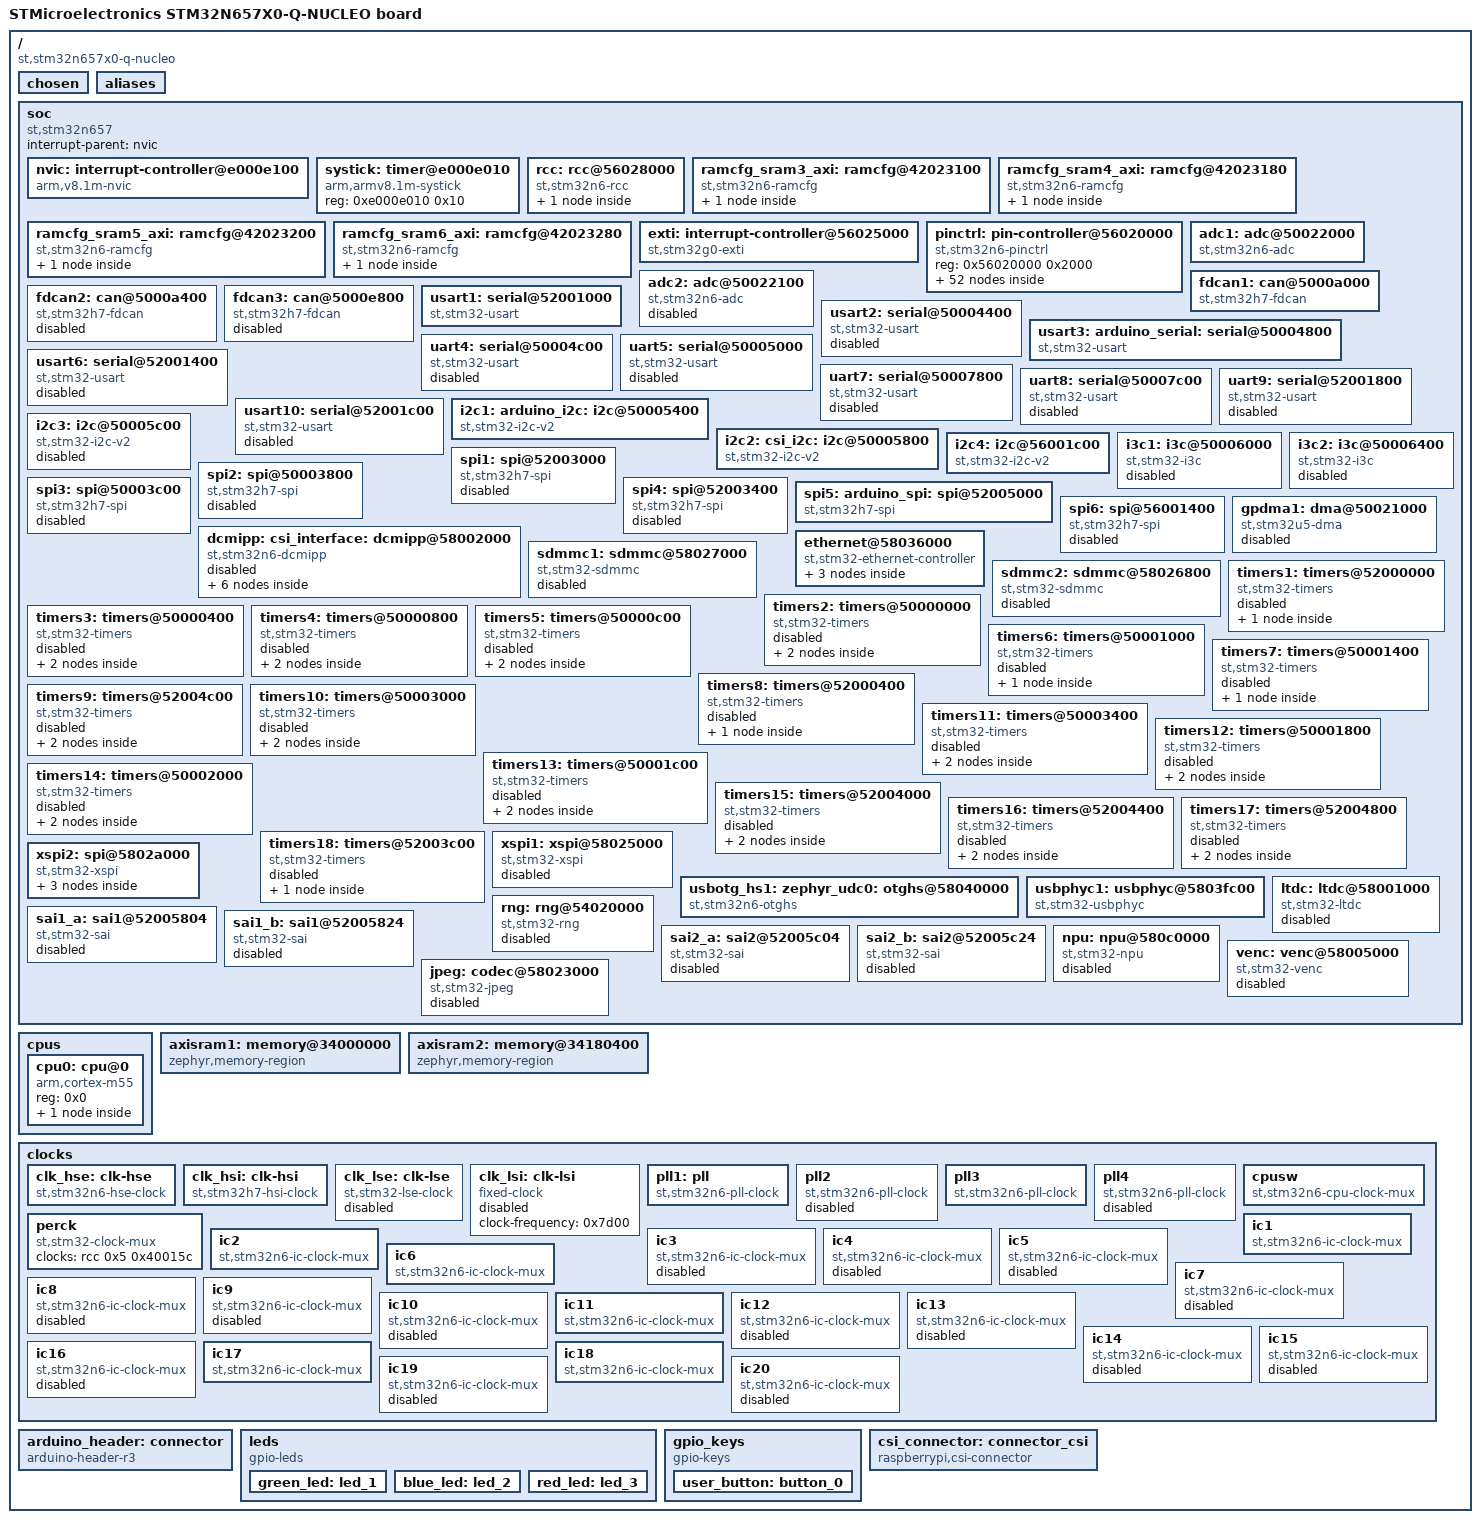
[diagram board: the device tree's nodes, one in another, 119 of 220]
/dts-v1/;

/* node '/' defined in zephyr/dts/common/skeleton.dtsi:9 */
/ {
	#address-cells = < 0x1 >;                                /* in zephyr/dts/common/skeleton.dtsi:10 */
	#size-cells = < 0x1 >;                                   /* in zephyr/dts/common/skeleton.dtsi:11 */
	model = "STMicroelectronics STM32N657X0-Q-NUCLEO board"; /* in zephyr/boards/st/nucleo_n657x0_q/nucleo_n657x0_q.dts:11 */
	compatible = "st,stm32n657x0-q-nucleo";                  /* in zephyr/boards/st/nucleo_n657x0_q/nucleo_n657x0_q.dts:12 */

	/* node '/chosen' defined in zephyr/dts/common/skeleton.dtsi:13 */
	chosen {
		zephyr,console = &usart1;    /* in zephyr/boards/st/nucleo_n657x0_q/nucleo_n657x0_q_common.dtsi:16 */
		zephyr,shell-uart = &usart1; /* in zephyr/boards/st/nucleo_n657x0_q/nucleo_n657x0_q_common.dtsi:17 */
		zephyr,sram = &axisram2;     /* in zephyr/boards/st/nucleo_n657x0_q/nucleo_n657x0_q_common.dtsi:18 */
		zephyr,canbus = &fdcan1;     /* in zephyr/boards/st/nucleo_n657x0_q/nucleo_n657x0_q_common.dtsi:19 */
		spi-flash0 = &mx25um51245g;  /* in zephyr/boards/st/nucleo_n657x0_q/nucleo_n657x0_q_common.dtsi:20 */
	};

	/* node '/aliases' defined in zephyr/dts/common/skeleton.dtsi:15 */
	aliases {
		led0 = &green_led;  /* in zephyr/boards/st/nucleo_n657x0_q/nucleo_n657x0_q_common.dtsi:53 */
		led1 = &blue_led;   /* in zephyr/boards/st/nucleo_n657x0_q/nucleo_n657x0_q_common.dtsi:54 */
		led2 = &red_led;    /* in zephyr/boards/st/nucleo_n657x0_q/nucleo_n657x0_q_common.dtsi:55 */
		sw0 = &user_button; /* in zephyr/boards/st/nucleo_n657x0_q/nucleo_n657x0_q_common.dtsi:56 */
	};

	/* node '/soc' defined in zephyr/dts/arm/armv8.1-m.dtsi:10 */
	soc {
		#address-cells = < 0x1 >;     /* in zephyr/dts/arm/armv8.1-m.dtsi:11 */
		#size-cells = < 0x1 >;        /* in zephyr/dts/arm/armv8.1-m.dtsi:12 */
		interrupt-parent = < &nvic >; /* in zephyr/dts/arm/armv8.1-m.dtsi:14 */
		ranges;                       /* in zephyr/dts/arm/armv8.1-m.dtsi:15 */
		compatible = "st,stm32n657",
		             "st,stm32n6",
		             "simple-bus";    /* in zephyr/dts/arm/st/n6/stm32n657.dtsi:11 */

		/* node '/soc/interrupt-controller@e000e100' defined in zephyr/dts/arm/armv8.1-m.dtsi:17 */
		nvic: interrupt-controller@e000e100 {
			#address-cells = < 0x1 >;            /* in zephyr/dts/arm/armv8.1-m.dtsi:18 */
			compatible = "arm,v8.1m-nvic";       /* in zephyr/dts/arm/armv8.1-m.dtsi:19 */
			reg = < 0xe000e100 0xc00 >;          /* in zephyr/dts/arm/armv8.1-m.dtsi:20 */
			interrupt-controller;                /* in zephyr/dts/arm/armv8.1-m.dtsi:21 */
			#interrupt-cells = < 0x2 >;          /* in zephyr/dts/arm/armv8.1-m.dtsi:22 */
			arm,num-irq-priority-bits = < 0x4 >; /* in zephyr/dts/arm/st/n6/stm32n6.dtsi:1336 */
			phandle = < 0x1 >;                   /* in zephyr/dts/arm/armv8.1-m.dtsi:14 */
		};

		/* node '/soc/timer@e000e010' defined in zephyr/dts/arm/armv8.1-m.dtsi:25 */
		systick: timer@e000e010 {
			compatible = "arm,armv8.1m-systick"; /* in zephyr/dts/arm/armv8.1-m.dtsi:26 */
			reg = < 0xe000e010 0x10 >;           /* in zephyr/dts/arm/armv8.1-m.dtsi:27 */
		};

		/* node '/soc/rcc@56028000' defined in zephyr/dts/arm/st/n6/stm32n6.dtsi:239 */
		rcc: rcc@56028000 {
			compatible = "st,stm32n6-rcc";    /* in zephyr/dts/arm/st/n6/stm32n6.dtsi:240 */
			clocks-controller;                /* in zephyr/dts/arm/st/n6/stm32n6.dtsi:241 */
			#clock-cells = < 0x2 >;           /* in zephyr/dts/arm/st/n6/stm32n6.dtsi:242 */
			reg = < 0x56028000 0x2000 >;      /* in zephyr/dts/arm/st/n6/stm32n6.dtsi:243 */
			clocks = < &ic2 >;                /* in zephyr/boards/st/nucleo_n657x0_q/nucleo_n657x0_q_common.dtsi:166 */
			clock-frequency = < 0x17d78400 >; /* in zephyr/boards/st/nucleo_n657x0_q/nucleo_n657x0_q_common.dtsi:167 */
			ahb-prescaler = < 0x2 >;          /* in zephyr/boards/st/nucleo_n657x0_q/nucleo_n657x0_q_common.dtsi:168 */
			timg-prescaler = < 0x2 >;         /* in zephyr/boards/st/nucleo_n657x0_q/nucleo_n657x0_q_common.dtsi:169 */
			phandle = < 0x3 >;                /* in zephyr/dts/arm/st/n6/stm32n6.dtsi:256 */

			/* node '/soc/rcc@56028000/reset-controller' defined in zephyr/dts/arm/st/n6/stm32n6.dtsi:245 */
			rctl: reset-controller {
				compatible = "st,stm32-rcc-rctl"; /* in zephyr/dts/arm/st/n6/stm32n6.dtsi:246 */
				#reset-cells = < 0x1 >;           /* in zephyr/dts/arm/st/n6/stm32n6.dtsi:247 */
				phandle = < 0x8 >;                /* in zephyr/dts/arm/st/n6/stm32n6.dtsi:513 */
			};
		};

		/* node '/soc/ramcfg@42023100' defined in zephyr/dts/arm/st/n6/stm32n6.dtsi:251 */
		ramcfg_sram3_axi: ramcfg@42023100 {
			compatible = "st,stm32n6-ramcfg"; /* in zephyr/dts/arm/st/n6/stm32n6.dtsi:252 */
			#address-cells = < 0x1 >;         /* in zephyr/dts/arm/st/n6/stm32n6.dtsi:253 */
			#size-cells = < 0x1 >;            /* in zephyr/dts/arm/st/n6/stm32n6.dtsi:254 */
			reg = < 0x42023100 0x80 >;        /* in zephyr/dts/arm/st/n6/stm32n6.dtsi:255 */
			clocks = < &rcc 0x24c 0x1 >,
			         < &rcc 0x254 0x1000 >;   /* in zephyr/dts/arm/st/n6/stm32n6.dtsi:256 */
			clock-names = "axisram",
			              "ramcfg";           /* in zephyr/dts/arm/st/n6/stm32n6.dtsi:257 */

			/* node '/soc/ramcfg@42023100/memory@34200000' defined in zephyr/dts/arm/st/n6/stm32n6.dtsi:259 */
			axisram3: memory@34200000 {
				compatible = "zephyr,memory-region",
				             "mmio-sram";            /* in zephyr/dts/arm/st/n6/stm32n6.dtsi:260 */
				zephyr,memory-region = "AXISRAM3";   /* in zephyr/dts/arm/st/n6/stm32n6.dtsi:261 */
				zephyr,memory-attr = < 0x100000 >;   /* in zephyr/dts/arm/st/n6/stm32n6.dtsi:262 */
				reg = < 0x34200000 0x70000 >;        /* in zephyr/dts/arm/st/n6/stm32n657X0.dtsi:23 */
				status = "disabled";                 /* in zephyr/dts/arm/st/n6/stm32n657X0.dtsi:24 */
			};
		};

		/* node '/soc/ramcfg@42023180' defined in zephyr/dts/arm/st/n6/stm32n6.dtsi:266 */
		ramcfg_sram4_axi: ramcfg@42023180 {
			compatible = "st,stm32n6-ramcfg"; /* in zephyr/dts/arm/st/n6/stm32n6.dtsi:267 */
			#address-cells = < 0x1 >;         /* in zephyr/dts/arm/st/n6/stm32n6.dtsi:268 */
			#size-cells = < 0x1 >;            /* in zephyr/dts/arm/st/n6/stm32n6.dtsi:269 */
			reg = < 0x42023180 0x80 >;        /* in zephyr/dts/arm/st/n6/stm32n6.dtsi:270 */
			clocks = < &rcc 0x24c 0x2 >,
			         < &rcc 0x254 0x1000 >;   /* in zephyr/dts/arm/st/n6/stm32n6.dtsi:271 */
			clock-names = "axisram",
			              "ramcfg";           /* in zephyr/dts/arm/st/n6/stm32n6.dtsi:272 */

			/* node '/soc/ramcfg@42023180/memory@34270000' defined in zephyr/dts/arm/st/n6/stm32n6.dtsi:274 */
			axisram4: memory@34270000 {
				compatible = "zephyr,memory-region",
				             "mmio-sram";            /* in zephyr/dts/arm/st/n6/stm32n6.dtsi:275 */
				zephyr,memory-region = "AXISRAM4";   /* in zephyr/dts/arm/st/n6/stm32n6.dtsi:276 */
				zephyr,memory-attr = < 0x100000 >;   /* in zephyr/dts/arm/st/n6/stm32n6.dtsi:277 */
				reg = < 0x34270000 0x70000 >;        /* in zephyr/dts/arm/st/n6/stm32n657X0.dtsi:30 */
				status = "disabled";                 /* in zephyr/dts/arm/st/n6/stm32n657X0.dtsi:31 */
			};
		};

		/* node '/soc/ramcfg@42023200' defined in zephyr/dts/arm/st/n6/stm32n6.dtsi:281 */
		ramcfg_sram5_axi: ramcfg@42023200 {
			compatible = "st,stm32n6-ramcfg"; /* in zephyr/dts/arm/st/n6/stm32n6.dtsi:282 */
			#address-cells = < 0x1 >;         /* in zephyr/dts/arm/st/n6/stm32n6.dtsi:283 */
			#size-cells = < 0x1 >;            /* in zephyr/dts/arm/st/n6/stm32n6.dtsi:284 */
			reg = < 0x42023200 0x80 >;        /* in zephyr/dts/arm/st/n6/stm32n6.dtsi:285 */
			clocks = < &rcc 0x24c 0x4 >,
			         < &rcc 0x254 0x1000 >;   /* in zephyr/dts/arm/st/n6/stm32n6.dtsi:286 */
			clock-names = "axisram",
			              "ramcfg";           /* in zephyr/dts/arm/st/n6/stm32n6.dtsi:287 */

			/* node '/soc/ramcfg@42023200/memory@342e0000' defined in zephyr/dts/arm/st/n6/stm32n6.dtsi:289 */
			axisram5: memory@342e0000 {
				compatible = "zephyr,memory-region",
				             "mmio-sram";            /* in zephyr/dts/arm/st/n6/stm32n6.dtsi:290 */
				zephyr,memory-region = "AXISRAM5";   /* in zephyr/dts/arm/st/n6/stm32n6.dtsi:291 */
				zephyr,memory-attr = < 0x100000 >;   /* in zephyr/dts/arm/st/n6/stm32n6.dtsi:292 */
				reg = < 0x342e0000 0x70000 >;        /* in zephyr/dts/arm/st/n6/stm32n657X0.dtsi:37 */
				status = "disabled";                 /* in zephyr/dts/arm/st/n6/stm32n657X0.dtsi:38 */
			};
		};

		/* node '/soc/ramcfg@42023280' defined in zephyr/dts/arm/st/n6/stm32n6.dtsi:296 */
		ramcfg_sram6_axi: ramcfg@42023280 {
			compatible = "st,stm32n6-ramcfg"; /* in zephyr/dts/arm/st/n6/stm32n6.dtsi:297 */
			#address-cells = < 0x1 >;         /* in zephyr/dts/arm/st/n6/stm32n6.dtsi:298 */
			#size-cells = < 0x1 >;            /* in zephyr/dts/arm/st/n6/stm32n6.dtsi:299 */
			reg = < 0x42023280 0x80 >;        /* in zephyr/dts/arm/st/n6/stm32n6.dtsi:300 */
			clocks = < &rcc 0x24c 0x8 >,
			         < &rcc 0x254 0x1000 >;   /* in zephyr/dts/arm/st/n6/stm32n6.dtsi:301 */
			clock-names = "axisram",
			              "ramcfg";           /* in zephyr/dts/arm/st/n6/stm32n6.dtsi:302 */

			/* node '/soc/ramcfg@42023280/memory@34350000' defined in zephyr/dts/arm/st/n6/stm32n6.dtsi:304 */
			axisram6: memory@34350000 {
				compatible = "zephyr,memory-region",
				             "mmio-sram";            /* in zephyr/dts/arm/st/n6/stm32n6.dtsi:305 */
				zephyr,memory-region = "AXISRAM6";   /* in zephyr/dts/arm/st/n6/stm32n6.dtsi:306 */
				zephyr,memory-attr = < 0x100000 >;   /* in zephyr/dts/arm/st/n6/stm32n6.dtsi:307 */
				reg = < 0x34350000 0x70000 >;        /* in zephyr/dts/arm/st/n6/stm32n657X0.dtsi:44 */
				status = "disabled";                 /* in zephyr/dts/arm/st/n6/stm32n657X0.dtsi:45 */
			};
		};

		/* node '/soc/interrupt-controller@56025000' defined in zephyr/dts/arm/st/n6/stm32n6.dtsi:311 */
		exti: interrupt-controller@56025000 {
			compatible = "st,stm32g0-exti",
			             "st,stm32-exti";   /* in zephyr/dts/arm/st/n6/stm32n6.dtsi:312 */
			interrupt-controller;           /* in zephyr/dts/arm/st/n6/stm32n6.dtsi:313 */
			#interrupt-cells = < 0x1 >;     /* in zephyr/dts/arm/st/n6/stm32n6.dtsi:314 */
			#address-cells = < 0x0 >;       /* in zephyr/dts/arm/st/n6/stm32n6.dtsi:315 */
			reg = < 0x56025000 0x400 >;     /* in zephyr/dts/arm/st/n6/stm32n6.dtsi:316 */
			clocks = < &rcc 0x278 0x1 >;    /* in zephyr/dts/arm/st/n6/stm32n6.dtsi:317 */
			num-lines = < 0x60 >;           /* in zephyr/dts/arm/st/n6/stm32n6.dtsi:318 */
			interrupts = < 0x14 0x0 >,
			             < 0x15 0x0 >,
			             < 0x16 0x0 >,
			             < 0x17 0x0 >,
			             < 0x18 0x0 >,
			             < 0x19 0x0 >,
			             < 0x1a 0x0 >,
			             < 0x1b 0x0 >,
			             < 0x1c 0x0 >,
			             < 0x1d 0x0 >,
			             < 0x1e 0x0 >,
			             < 0x1f 0x0 >,
			             < 0x20 0x0 >,
			             < 0x21 0x0 >,
			             < 0x22 0x0 >,
			             < 0x23 0x0 >;      /* in zephyr/dts/arm/st/n6/stm32n6.dtsi:319 */
			interrupt-names = "line0",
			                  "line1",
			                  "line2",
			                  "line3",
			                  "line4",
			                  "line5",
			                  "line6",
			                  "line7",
			                  "line8",
			                  "line9",
			                  "line10",
			                  "line11",
			                  "line12",
			                  "line13",
			                  "line14",
			                  "line15";     /* in zephyr/dts/arm/st/n6/stm32n6.dtsi:323 */
			line-ranges = < 0x0 0x1 >,
			              < 0x1 0x1 >,
			              < 0x2 0x1 >,
			              < 0x3 0x1 >,
			              < 0x4 0x1 >,
			              < 0x5 0x1 >,
			              < 0x6 0x1 >,
			              < 0x7 0x1 >,
			              < 0x8 0x1 >,
			              < 0x9 0x1 >,
			              < 0xa 0x1 >,
			              < 0xb 0x1 >,
			              < 0xc 0x1 >,
			              < 0xd 0x1 >,
			              < 0xe 0x1 >,
			              < 0xf 0x1 >;      /* in zephyr/dts/arm/st/n6/stm32n6.dtsi:327 */
		};

		/* node '/soc/pin-controller@56020000' defined in zephyr/dts/arm/st/n6/stm32n6.dtsi:333 */
		pinctrl: pin-controller@56020000 {
			compatible = "st,stm32n6-pinctrl",
			             "st,stm32-pinctrl";   /* in zephyr/dts/arm/st/n6/stm32n6.dtsi:334 */
			#address-cells = < 0x1 >;          /* in zephyr/dts/arm/st/n6/stm32n6.dtsi:335 */
			#size-cells = < 0x1 >;             /* in zephyr/dts/arm/st/n6/stm32n6.dtsi:336 */
			reg = < 0x56020000 0x2000 >;       /* in zephyr/dts/arm/st/n6/stm32n6.dtsi:337 */

			/* node '/soc/pin-controller@56020000/gpio@56020000' defined in zephyr/dts/arm/st/n6/stm32n6.dtsi:339 */
			gpioa: gpio@56020000 {
				compatible = "st,stm32-gpio"; /* in zephyr/dts/arm/st/n6/stm32n6.dtsi:340 */
				gpio-controller;              /* in zephyr/dts/arm/st/n6/stm32n6.dtsi:341 */
				#gpio-cells = < 0x2 >;        /* in zephyr/dts/arm/st/n6/stm32n6.dtsi:342 */
				reg = < 0x56020000 0x400 >;   /* in zephyr/dts/arm/st/n6/stm32n6.dtsi:343 */
				clocks = < &rcc 0x25c 0x1 >;  /* in zephyr/dts/arm/st/n6/stm32n6.dtsi:344 */
				phandle = < 0x2f >;           /* in zephyr/boards/st/nucleo_n657x0_q/arduino_r3_connector.dtsi:15 */

				/* node '/soc/pin-controller@56020000/gpio@56020000/csi-gpio1-hog' defined in zephyr/boards/st/nucleo_n657x0_q/nucleo_n657x0_q_common.dtsi:79 */
				csi_gpio1_hog: csi-gpio1-hog {
					gpio-hog;            /* in zephyr/boards/st/nucleo_n657x0_q/nucleo_n657x0_q_common.dtsi:80 */
					gpios = < 0x0 0x0 >; /* in zephyr/boards/st/nucleo_n657x0_q/nucleo_n657x0_q_common.dtsi:81 */
					status = "disabled"; /* in zephyr/boards/st/nucleo_n657x0_q/nucleo_n657x0_q_common.dtsi:83 */
				};
			};

			/* node '/soc/pin-controller@56020000/gpio@56020400' defined in zephyr/dts/arm/st/n6/stm32n6.dtsi:347 */
			gpiob: gpio@56020400 {
				compatible = "st,stm32-gpio"; /* in zephyr/dts/arm/st/n6/stm32n6.dtsi:348 */
				gpio-controller;              /* in zephyr/dts/arm/st/n6/stm32n6.dtsi:349 */
				#gpio-cells = < 0x2 >;        /* in zephyr/dts/arm/st/n6/stm32n6.dtsi:350 */
				reg = < 0x56020400 0x400 >;   /* in zephyr/dts/arm/st/n6/stm32n6.dtsi:351 */
				clocks = < &rcc 0x25c 0x2 >;  /* in zephyr/dts/arm/st/n6/stm32n6.dtsi:352 */
			};

			/* node '/soc/pin-controller@56020000/gpio@56020800' defined in zephyr/dts/arm/st/n6/stm32n6.dtsi:355 */
			gpioc: gpio@56020800 {
				compatible = "st,stm32-gpio"; /* in zephyr/dts/arm/st/n6/stm32n6.dtsi:356 */
				gpio-controller;              /* in zephyr/dts/arm/st/n6/stm32n6.dtsi:357 */
				#gpio-cells = < 0x2 >;        /* in zephyr/dts/arm/st/n6/stm32n6.dtsi:358 */
				reg = < 0x56020800 0x400 >;   /* in zephyr/dts/arm/st/n6/stm32n6.dtsi:359 */
				clocks = < &rcc 0x25c 0x4 >;  /* in zephyr/dts/arm/st/n6/stm32n6.dtsi:360 */
				phandle = < 0x34 >;           /* in zephyr/boards/st/nucleo_n657x0_q/arduino_r3_connector.dtsi:15 */
			};

			/* node '/soc/pin-controller@56020000/gpio@56020c00' defined in zephyr/dts/arm/st/n6/stm32n6.dtsi:363 */
			gpiod: gpio@56020c00 {
				compatible = "st,stm32-gpio"; /* in zephyr/dts/arm/st/n6/stm32n6.dtsi:364 */
				gpio-controller;              /* in zephyr/dts/arm/st/n6/stm32n6.dtsi:365 */
				#gpio-cells = < 0x2 >;        /* in zephyr/dts/arm/st/n6/stm32n6.dtsi:366 */
				reg = < 0x56020c00 0x400 >;   /* in zephyr/dts/arm/st/n6/stm32n6.dtsi:367 */
				clocks = < &rcc 0x25c 0x8 >;  /* in zephyr/dts/arm/st/n6/stm32n6.dtsi:368 */
				phandle = < 0x32 >;           /* in zephyr/boards/st/nucleo_n657x0_q/arduino_r3_connector.dtsi:15 */
			};

			/* node '/soc/pin-controller@56020000/gpio@56021000' defined in zephyr/dts/arm/st/n6/stm32n6.dtsi:371 */
			gpioe: gpio@56021000 {
				compatible = "st,stm32-gpio"; /* in zephyr/dts/arm/st/n6/stm32n6.dtsi:372 */
				gpio-controller;              /* in zephyr/dts/arm/st/n6/stm32n6.dtsi:373 */
				#gpio-cells = < 0x2 >;        /* in zephyr/dts/arm/st/n6/stm32n6.dtsi:374 */
				reg = < 0x56021000 0x400 >;   /* in zephyr/dts/arm/st/n6/stm32n6.dtsi:375 */
				clocks = < &rcc 0x25c 0x10 >; /* in zephyr/dts/arm/st/n6/stm32n6.dtsi:376 */
				phandle = < 0x33 >;           /* in zephyr/boards/st/nucleo_n657x0_q/arduino_r3_connector.dtsi:15 */
			};

			/* node '/soc/pin-controller@56020000/gpio@56021400' defined in zephyr/dts/arm/st/n6/stm32n6.dtsi:379 */
			gpiof: gpio@56021400 {
				compatible = "st,stm32-gpio"; /* in zephyr/dts/arm/st/n6/stm32n6.dtsi:380 */
				gpio-controller;              /* in zephyr/dts/arm/st/n6/stm32n6.dtsi:381 */
				#gpio-cells = < 0x2 >;        /* in zephyr/dts/arm/st/n6/stm32n6.dtsi:382 */
				reg = < 0x56021400 0x400 >;   /* in zephyr/dts/arm/st/n6/stm32n6.dtsi:383 */
				clocks = < &rcc 0x25c 0x20 >; /* in zephyr/dts/arm/st/n6/stm32n6.dtsi:384 */
				phandle = < 0x30 >;           /* in zephyr/boards/st/nucleo_n657x0_q/arduino_r3_connector.dtsi:15 */
			};

			/* node '/soc/pin-controller@56020000/gpio@56021800' defined in zephyr/dts/arm/st/n6/stm32n6.dtsi:387 */
			gpiog: gpio@56021800 {
				compatible = "st,stm32-gpio"; /* in zephyr/dts/arm/st/n6/stm32n6.dtsi:388 */
				gpio-controller;              /* in zephyr/dts/arm/st/n6/stm32n6.dtsi:389 */
				#gpio-cells = < 0x2 >;        /* in zephyr/dts/arm/st/n6/stm32n6.dtsi:390 */
				reg = < 0x56021800 0x400 >;   /* in zephyr/dts/arm/st/n6/stm32n6.dtsi:391 */
				clocks = < &rcc 0x25c 0x40 >; /* in zephyr/dts/arm/st/n6/stm32n6.dtsi:392 */
				phandle = < 0x31 >;           /* in zephyr/boards/st/nucleo_n657x0_q/arduino_r3_connector.dtsi:15 */
			};

			/* node '/soc/pin-controller@56020000/gpio@56021c00' defined in zephyr/dts/arm/st/n6/stm32n6.dtsi:395 */
			gpioh: gpio@56021c00 {
				compatible = "st,stm32-gpio"; /* in zephyr/dts/arm/st/n6/stm32n6.dtsi:396 */
				gpio-controller;              /* in zephyr/dts/arm/st/n6/stm32n6.dtsi:397 */
				#gpio-cells = < 0x2 >;        /* in zephyr/dts/arm/st/n6/stm32n6.dtsi:398 */
				reg = < 0x56021c00 0x400 >;   /* in zephyr/dts/arm/st/n6/stm32n6.dtsi:399 */
				clocks = < &rcc 0x25c 0x80 >; /* in zephyr/dts/arm/st/n6/stm32n6.dtsi:400 */
				phandle = < 0x35 >;           /* in zephyr/boards/st/nucleo_n657x0_q/arduino_r3_connector.dtsi:15 */
			};

			/* node '/soc/pin-controller@56020000/gpio@56023400' defined in zephyr/dts/arm/st/n6/stm32n6.dtsi:403 */
			gpion: gpio@56023400 {
				compatible = "st,stm32-gpio";   /* in zephyr/dts/arm/st/n6/stm32n6.dtsi:404 */
				gpio-controller;                /* in zephyr/dts/arm/st/n6/stm32n6.dtsi:405 */
				#gpio-cells = < 0x2 >;          /* in zephyr/dts/arm/st/n6/stm32n6.dtsi:406 */
				reg = < 0x56023400 0x400 >;     /* in zephyr/dts/arm/st/n6/stm32n6.dtsi:407 */
				clocks = < &rcc 0x25c 0x2000 >; /* in zephyr/dts/arm/st/n6/stm32n6.dtsi:408 */
			};

			/* node '/soc/pin-controller@56020000/gpio@56023800' defined in zephyr/dts/arm/st/n6/stm32n6.dtsi:411 */
			gpioo: gpio@56023800 {
				compatible = "st,stm32-gpio";   /* in zephyr/dts/arm/st/n6/stm32n6.dtsi:412 */
				gpio-controller;                /* in zephyr/dts/arm/st/n6/stm32n6.dtsi:413 */
				#gpio-cells = < 0x2 >;          /* in zephyr/dts/arm/st/n6/stm32n6.dtsi:414 */
				reg = < 0x56023800 0x400 >;     /* in zephyr/dts/arm/st/n6/stm32n6.dtsi:415 */
				clocks = < &rcc 0x25c 0x4000 >; /* in zephyr/dts/arm/st/n6/stm32n6.dtsi:416 */
				phandle = < 0x36 >;             /* in zephyr/boards/st/nucleo_n657x0_q/nucleo_n657x0_q_common.dtsi:64 */

				/* node '/soc/pin-controller@56020000/gpio@56023800/csi-gpio0-hog' defined in zephyr/boards/st/nucleo_n657x0_q/nucleo_n657x0_q_common.dtsi:70 */
				csi_gpio0_hog: csi-gpio0-hog {
					gpio-hog;            /* in zephyr/boards/st/nucleo_n657x0_q/nucleo_n657x0_q_common.dtsi:71 */
					gpios = < 0x5 0x0 >; /* in zephyr/boards/st/nucleo_n657x0_q/nucleo_n657x0_q_common.dtsi:72 */
					status = "disabled"; /* in zephyr/boards/st/nucleo_n657x0_q/nucleo_n657x0_q_common.dtsi:74 */
				};
			};

			/* node '/soc/pin-controller@56020000/gpio@56023c00' defined in zephyr/dts/arm/st/n6/stm32n6.dtsi:419 */
			gpiop: gpio@56023c00 {
				compatible = "st,stm32-gpio";   /* in zephyr/dts/arm/st/n6/stm32n6.dtsi:420 */
				gpio-controller;                /* in zephyr/dts/arm/st/n6/stm32n6.dtsi:421 */
				#gpio-cells = < 0x2 >;          /* in zephyr/dts/arm/st/n6/stm32n6.dtsi:422 */
				reg = < 0x56023c00 0x400 >;     /* in zephyr/dts/arm/st/n6/stm32n6.dtsi:423 */
				clocks = < &rcc 0x25c 0x8000 >; /* in zephyr/dts/arm/st/n6/stm32n6.dtsi:424 */
			};

			/* node '/soc/pin-controller@56020000/gpio@56024000' defined in zephyr/dts/arm/st/n6/stm32n6.dtsi:427 */
			gpioq: gpio@56024000 {
				compatible = "st,stm32-gpio";    /* in zephyr/dts/arm/st/n6/stm32n6.dtsi:428 */
				gpio-controller;                 /* in zephyr/dts/arm/st/n6/stm32n6.dtsi:429 */
				#gpio-cells = < 0x2 >;           /* in zephyr/dts/arm/st/n6/stm32n6.dtsi:430 */
				reg = < 0x56024000 0x400 >;      /* in zephyr/dts/arm/st/n6/stm32n6.dtsi:431 */
				clocks = < &rcc 0x25c 0x10000 >; /* in zephyr/dts/arm/st/n6/stm32n6.dtsi:432 */
			};

			/* node '/soc/pin-controller@56020000/adc1_inp10_pa9' defined in modules/hal/stm32/dts/st/n6/stm32n657x0hxq-pinctrl.dtsi:39 */
			adc1_inp10_pa9: adc1_inp10_pa9 {
				pinmux = < 0x130 >; /* in modules/hal/stm32/dts/st/n6/stm32n657x0hxq-pinctrl.dtsi:40 */
				phandle = < 0x4 >;  /* in zephyr/boards/st/nucleo_n657x0_q/nucleo_n657x0_q_common.dtsi:176 */
			};

			/* node '/soc/pin-controller@56020000/adc1_inp11_pa10' defined in modules/hal/stm32/dts/st/n6/stm32n657x0hxq-pinctrl.dtsi:47 */
			adc1_inp11_pa10: adc1_inp11_pa10 {
				pinmux = < 0x150 >; /* in modules/hal/stm32/dts/st/n6/stm32n657x0hxq-pinctrl.dtsi:48 */
				phandle = < 0x5 >;  /* in zephyr/boards/st/nucleo_n657x0_q/nucleo_n657x0_q_common.dtsi:176 */
			};

			/* node '/soc/pin-controller@56020000/eth1_mdio_pf4' defined in modules/hal/stm32/dts/st/n6/stm32n657x0hxq-pinctrl.dtsi:1547 */
			eth1_mdio_pf4: eth1_mdio_pf4 {
				pinmux = < 0xa8b >;            /* in modules/hal/stm32/dts/st/n6/stm32n657x0hxq-pinctrl.dtsi:1548 */
				slew-rate = "very-high-speed"; /* in modules/hal/stm32/dts/st/n6/stm32n657x0hxq-pinctrl.dtsi:1549 */
				phandle = < 0x1f >;            /* in zephyr/boards/st/nucleo_n657x0_q/nucleo_n657x0_q_common.dtsi:263 */
			};

			/* node '/soc/pin-controller@56020000/eth1_mdc_pg11' defined in modules/hal/stm32/dts/st/n6/stm32n657x0hxq-pinctrl.dtsi:1567 */
			eth1_mdc_pg11: eth1_mdc_pg11 {
				pinmux = < 0xd6b >;            /* in modules/hal/stm32/dts/st/n6/stm32n657x0hxq-pinctrl.dtsi:1568 */
				slew-rate = "very-high-speed"; /* in modules/hal/stm32/dts/st/n6/stm32n657x0hxq-pinctrl.dtsi:1569 */
				phandle = < 0x20 >;            /* in zephyr/boards/st/nucleo_n657x0_q/nucleo_n657x0_q_common.dtsi:263 */
			};

			/* node '/soc/pin-controller@56020000/eth1_rmii_ref_clk_pf7' defined in modules/hal/stm32/dts/st/n6/stm32n657x0hxq-pinctrl.dtsi:1733 */
			eth1_rmii_ref_clk_pf7: eth1_rmii_ref_clk_pf7 {
				pinmux = < 0xaeb >;            /* in modules/hal/stm32/dts/st/n6/stm32n657x0hxq-pinctrl.dtsi:1734 */
				slew-rate = "very-high-speed"; /* in modules/hal/stm32/dts/st/n6/stm32n657x0hxq-pinctrl.dtsi:1735 */
				phandle = < 0x17 >;            /* in zephyr/boards/st/nucleo_n657x0_q/nucleo_n657x0_q_common.dtsi:249 */
			};

			/* node '/soc/pin-controller@56020000/eth1_rmii_crs_dv_pf10' defined in modules/hal/stm32/dts/st/n6/stm32n657x0hxq-pinctrl.dtsi:1738 */
			eth1_rmii_crs_dv_pf10: eth1_rmii_crs_dv_pf10 {
				pinmux = < 0xb4b >;            /* in modules/hal/stm32/dts/st/n6/stm32n657x0hxq-pinctrl.dtsi:1739 */
				slew-rate = "very-high-speed"; /* in modules/hal/stm32/dts/st/n6/stm32n657x0hxq-pinctrl.dtsi:1740 */
				phandle = < 0x18 >;            /* in zephyr/boards/st/nucleo_n657x0_q/nucleo_n657x0_q_common.dtsi:249 */
			};

			/* node '/soc/pin-controller@56020000/eth1_rmii_tx_en_pf11' defined in modules/hal/stm32/dts/st/n6/stm32n657x0hxq-pinctrl.dtsi:1743 */
			eth1_rmii_tx_en_pf11: eth1_rmii_tx_en_pf11 {
				pinmux = < 0xb6b >;            /* in modules/hal/stm32/dts/st/n6/stm32n657x0hxq-pinctrl.dtsi:1744 */
				slew-rate = "very-high-speed"; /* in modules/hal/stm32/dts/st/n6/stm32n657x0hxq-pinctrl.dtsi:1745 */
				phandle = < 0x1b >;            /* in zephyr/boards/st/nucleo_n657x0_q/nucleo_n657x0_q_common.dtsi:249 */
			};

			/* node '/soc/pin-controller@56020000/eth1_rmii_txd0_pf12' defined in modules/hal/stm32/dts/st/n6/stm32n657x0hxq-pinctrl.dtsi:1748 */
			eth1_rmii_txd0_pf12: eth1_rmii_txd0_pf12 {
				pinmux = < 0xb8b >;            /* in modules/hal/stm32/dts/st/n6/stm32n657x0hxq-pinctrl.dtsi:1749 */
				slew-rate = "very-high-speed"; /* in modules/hal/stm32/dts/st/n6/stm32n657x0hxq-pinctrl.dtsi:1750 */
				phandle = < 0x1c >;            /* in zephyr/boards/st/nucleo_n657x0_q/nucleo_n657x0_q_common.dtsi:249 */
			};

			/* node '/soc/pin-controller@56020000/eth1_rmii_txd1_pf13' defined in modules/hal/stm32/dts/st/n6/stm32n657x0hxq-pinctrl.dtsi:1753 */
			eth1_rmii_txd1_pf13: eth1_rmii_txd1_pf13 {
				pinmux = < 0xbab >;            /* in modules/hal/stm32/dts/st/n6/stm32n657x0hxq-pinctrl.dtsi:1754 */
				slew-rate = "very-high-speed"; /* in modules/hal/stm32/dts/st/n6/stm32n657x0hxq-pinctrl.dtsi:1755 */
				phandle = < 0x1d >;            /* in zephyr/boards/st/nucleo_n657x0_q/nucleo_n657x0_q_common.dtsi:249 */
			};

			/* node '/soc/pin-controller@56020000/eth1_rmii_rxd0_pf14' defined in modules/hal/stm32/dts/st/n6/stm32n657x0hxq-pinctrl.dtsi:1758 */
			eth1_rmii_rxd0_pf14: eth1_rmii_rxd0_pf14 {
				pinmux = < 0xbcb >;            /* in modules/hal/stm32/dts/st/n6/stm32n657x0hxq-pinctrl.dtsi:1759 */
				slew-rate = "very-high-speed"; /* in modules/hal/stm32/dts/st/n6/stm32n657x0hxq-pinctrl.dtsi:1760 */
				phandle = < 0x19 >;            /* in zephyr/boards/st/nucleo_n657x0_q/nucleo_n657x0_q_common.dtsi:249 */
			};

			/* node '/soc/pin-controller@56020000/eth1_rmii_rxd1_pf15' defined in modules/hal/stm32/dts/st/n6/stm32n657x0hxq-pinctrl.dtsi:1763 */
			eth1_rmii_rxd1_pf15: eth1_rmii_rxd1_pf15 {
				pinmux = < 0xbeb >;            /* in modules/hal/stm32/dts/st/n6/stm32n657x0hxq-pinctrl.dtsi:1764 */
				slew-rate = "very-high-speed"; /* in modules/hal/stm32/dts/st/n6/stm32n657x0hxq-pinctrl.dtsi:1765 */
				phandle = < 0x1a >;            /* in zephyr/boards/st/nucleo_n657x0_q/nucleo_n657x0_q_common.dtsi:249 */
			};

			/* node '/soc/pin-controller@56020000/fdcan1_rx_pd0' defined in modules/hal/stm32/dts/st/n6/stm32n657x0hxq-pinctrl.dtsi:1779 */
			fdcan1_rx_pd0: fdcan1_rx_pd0 {
				pinmux = < 0x606 >; /* in modules/hal/stm32/dts/st/n6/stm32n657x0hxq-pinctrl.dtsi:1780 */
				phandle = < 0x6 >;  /* in zephyr/boards/st/nucleo_n657x0_q/nucleo_n657x0_q_common.dtsi:185 */
			};

			/* node '/soc/pin-controller@56020000/fdcan1_tx_ph2' defined in modules/hal/stm32/dts/st/n6/stm32n657x0hxq-pinctrl.dtsi:1817 */
			fdcan1_tx_ph2: fdcan1_tx_ph2 {
				pinmux = < 0xe46 >; /* in modules/hal/stm32/dts/st/n6/stm32n657x0hxq-pinctrl.dtsi:1818 */
				phandle = < 0x7 >;  /* in zephyr/boards/st/nucleo_n657x0_q/nucleo_n657x0_q_common.dtsi:185 */
			};

			/* node '/soc/pin-controller@56020000/i2c1_scl_ph9' defined in modules/hal/stm32/dts/st/n6/stm32n657x0hxq-pinctrl.dtsi:2601 */
			i2c1_scl_ph9: i2c1_scl_ph9 {
				pinmux = < 0xf24 >; /* in modules/hal/stm32/dts/st/n6/stm32n657x0hxq-pinctrl.dtsi:2602 */
				bias-pull-up;       /* in modules/hal/stm32/dts/st/n6/stm32n657x0hxq-pinctrl.dtsi:2603 */
				drive-open-drain;   /* in modules/hal/stm32/dts/st/n6/stm32n657x0hxq-pinctrl.dtsi:2604 */
				phandle = < 0xd >;  /* in zephyr/boards/st/nucleo_n657x0_q/nucleo_n657x0_q_common.dtsi:193 */
			};

			/* node '/soc/pin-controller@56020000/i2c2_scl_pb10' defined in modules/hal/stm32/dts/st/n6/stm32n657x0hxq-pinctrl.dtsi:2607 */
			i2c2_scl_pb10: i2c2_scl_pb10 {
				pinmux = < 0x344 >; /* in modules/hal/stm32/dts/st/n6/stm32n657x0hxq-pinctrl.dtsi:2608 */
				bias-pull-up;       /* in modules/hal/stm32/dts/st/n6/stm32n657x0hxq-pinctrl.dtsi:2609 */
				drive-open-drain;   /* in modules/hal/stm32/dts/st/n6/stm32n657x0hxq-pinctrl.dtsi:2610 */
				phandle = < 0xf >;  /* in zephyr/boards/st/nucleo_n657x0_q/nucleo_n657x0_q_common.dtsi:202 */
			};

			/* node '/soc/pin-controller@56020000/i2c4_scl_pe13' defined in modules/hal/stm32/dts/st/n6/stm32n657x0hxq-pinctrl.dtsi:2631 */
			i2c4_scl_pe13: i2c4_scl_pe13 {
				pinmux = < 0x9a4 >; /* in modules/hal/stm32/dts/st/n6/stm32n657x0hxq-pinctrl.dtsi:2632 */
				bias-pull-up;       /* in modules/hal/stm32/dts/st/n6/stm32n657x0hxq-pinctrl.dtsi:2633 */
				drive-open-drain;   /* in modules/hal/stm32/dts/st/n6/stm32n657x0hxq-pinctrl.dtsi:2634 */
				phandle = < 0x11 >; /* in zephyr/boards/st/nucleo_n657x0_q/nucleo_n657x0_q_common.dtsi:211 */
			};

			/* node '/soc/pin-controller@56020000/i2c1_sda_pc1' defined in modules/hal/stm32/dts/st/n6/stm32n657x0hxq-pinctrl.dtsi:2639 */
			i2c1_sda_pc1: i2c1_sda_pc1 {
				pinmux = < 0x424 >; /* in modules/hal/stm32/dts/st/n6/stm32n657x0hxq-pinctrl.dtsi:2640 */
				bias-pull-up;       /* in modules/hal/stm32/dts/st/n6/stm32n657x0hxq-pinctrl.dtsi:2641 */
				drive-open-drain;   /* in modules/hal/stm32/dts/st/n6/stm32n657x0hxq-pinctrl.dtsi:2642 */
				phandle = < 0xe >;  /* in zephyr/boards/st/nucleo_n657x0_q/nucleo_n657x0_q_common.dtsi:193 */
			};

			/* node '/soc/pin-controller@56020000/i2c2_sda_pb11' defined in modules/hal/stm32/dts/st/n6/stm32n657x0hxq-pinctrl.dtsi:2651 */
			i2c2_sda_pb11: i2c2_sda_pb11 {
				pinmux = < 0x364 >; /* in modules/hal/stm32/dts/st/n6/stm32n657x0hxq-pinctrl.dtsi:2652 */
				bias-pull-up;       /* in modules/hal/stm32/dts/st/n6/stm32n657x0hxq-pinctrl.dtsi:2653 */
				drive-open-drain;   /* in modules/hal/stm32/dts/st/n6/stm32n657x0hxq-pinctrl.dtsi:2654 */
				phandle = < 0x10 >; /* in zephyr/boards/st/nucleo_n657x0_q/nucleo_n657x0_q_common.dtsi:202 */
			};

			/* node '/soc/pin-controller@56020000/i2c4_sda_pe14' defined in modules/hal/stm32/dts/st/n6/stm32n657x0hxq-pinctrl.dtsi:2693 */
			i2c4_sda_pe14: i2c4_sda_pe14 {
				pinmux = < 0x9c4 >; /* in modules/hal/stm32/dts/st/n6/stm32n657x0hxq-pinctrl.dtsi:2694 */
				bias-pull-up;       /* in modules/hal/stm32/dts/st/n6/stm32n657x0hxq-pinctrl.dtsi:2695 */
				drive-open-drain;   /* in modules/hal/stm32/dts/st/n6/stm32n657x0hxq-pinctrl.dtsi:2696 */
				phandle = < 0x12 >; /* in zephyr/boards/st/nucleo_n657x0_q/nucleo_n657x0_q_common.dtsi:211 */
			};

			/* node '/soc/pin-controller@56020000/spi5_miso_pg1' defined in modules/hal/stm32/dts/st/n6/stm32n657x0hxq-pinctrl.dtsi:3744 */
			spi5_miso_pg1: spi5_miso_pg1 {
				pinmux = < 0xc25 >; /* in modules/hal/stm32/dts/st/n6/stm32n657x0hxq-pinctrl.dtsi:3745 */
				bias-pull-down;     /* in modules/hal/stm32/dts/st/n6/stm32n657x0hxq-pinctrl.dtsi:3746 */
				phandle = < 0x15 >; /* in zephyr/boards/st/nucleo_n657x0_q/nucleo_n657x0_q_common.dtsi:220 */
			};

			/* node '/soc/pin-controller@56020000/spi5_mosi_pg2' defined in modules/hal/stm32/dts/st/n6/stm32n657x0hxq-pinctrl.dtsi:3851 */
			spi5_mosi_pg2: spi5_mosi_pg2 {
				pinmux = < 0xc45 >; /* in modules/hal/stm32/dts/st/n6/stm32n657x0hxq-pinctrl.dtsi:3852 */
				bias-pull-down;     /* in modules/hal/stm32/dts/st/n6/stm32n657x0hxq-pinctrl.dtsi:3853 */
				phandle = < 0x16 >; /* in zephyr/boards/st/nucleo_n657x0_q/nucleo_n657x0_q_common.dtsi:220 */
			};

			/* node '/soc/pin-controller@56020000/spi5_nss_pa3' defined in modules/hal/stm32/dts/st/n6/stm32n657x0hxq-pinctrl.dtsi:3938 */
			spi5_nss_pa3: spi5_nss_pa3 {
				pinmux = < 0x65 >;  /* in modules/hal/stm32/dts/st/n6/stm32n657x0hxq-pinctrl.dtsi:3939 */
				bias-pull-up;       /* in modules/hal/stm32/dts/st/n6/stm32n657x0hxq-pinctrl.dtsi:3940 */
				phandle = < 0x13 >; /* in zephyr/boards/st/nucleo_n657x0_q/nucleo_n657x0_q_common.dtsi:220 */
			};

			/* node '/soc/pin-controller@56020000/spi5_sck_pe15' defined in modules/hal/stm32/dts/st/n6/stm32n657x0hxq-pinctrl.dtsi:4053 */
			spi5_sck_pe15: spi5_sck_pe15 {
				pinmux = < 0x9e5 >;            /* in modules/hal/stm32/dts/st/n6/stm32n657x0hxq-pinctrl.dtsi:4054 */
				bias-pull-down;                /* in modules/hal/stm32/dts/st/n6/stm32n657x0hxq-pinctrl.dtsi:4055 */
				slew-rate = "very-high-speed"; /* in modules/hal/stm32/dts/st/n6/stm32n657x0hxq-pinctrl.dtsi:4056 */
				phandle = < 0x14 >;            /* in zephyr/boards/st/nucleo_n657x0_q/nucleo_n657x0_q_common.dtsi:220 */
			};

			/* node '/soc/pin-controller@56020000/usart1_rx_pe6' defined in modules/hal/stm32/dts/st/n6/stm32n657x0hxq-pinctrl.dtsi:4835 */
			usart1_rx_pe6: usart1_rx_pe6 {
				pinmux = < 0x8c7 >; /* in modules/hal/stm32/dts/st/n6/stm32n657x0hxq-pinctrl.dtsi:4836 */
				phandle = < 0xa >;  /* in zephyr/boards/st/nucleo_n657x0_q/nucleo_n657x0_q_common.dtsi:228 */
			};

			/* node '/soc/pin-controller@56020000/usart3_rx_pd9' defined in modules/hal/stm32/dts/st/n6/stm32n657x0hxq-pinctrl.dtsi:4863 */
			usart3_rx_pd9: usart3_rx_pd9 {
				pinmux = < 0x727 >; /* in modules/hal/stm32/dts/st/n6/stm32n657x0hxq-pinctrl.dtsi:4864 */
				phandle = < 0xc >;  /* in zephyr/boards/st/nucleo_n657x0_q/nucleo_n657x0_q_common.dtsi:237 */
			};

			/* node '/soc/pin-controller@56020000/usart1_tx_pe5' defined in modules/hal/stm32/dts/st/n6/stm32n657x0hxq-pinctrl.dtsi:4991 */
			usart1_tx_pe5: usart1_tx_pe5 {
				pinmux = < 0x8a7 >; /* in modules/hal/stm32/dts/st/n6/stm32n657x0hxq-pinctrl.dtsi:4992 */
				bias-pull-up;       /* in modules/hal/stm32/dts/st/n6/stm32n657x0hxq-pinctrl.dtsi:4993 */
				phandle = < 0x9 >;  /* in zephyr/boards/st/nucleo_n657x0_q/nucleo_n657x0_q_common.dtsi:228 */
			};

			/* node '/soc/pin-controller@56020000/usart3_tx_pd8' defined in modules/hal/stm32/dts/st/n6/stm32n657x0hxq-pinctrl.dtsi:5031 */
			usart3_tx_pd8: usart3_tx_pd8 {
				pinmux = < 0x707 >; /* in modules/hal/stm32/dts/st/n6/stm32n657x0hxq-pinctrl.dtsi:5032 */
				bias-pull-up;       /* in modules/hal/stm32/dts/st/n6/stm32n657x0hxq-pinctrl.dtsi:5033 */
				phandle = < 0xb >;  /* in zephyr/boards/st/nucleo_n657x0_q/nucleo_n657x0_q_common.dtsi:237 */
			};

			/* node '/soc/pin-controller@56020000/xspim_p2_dqs0_pn0' defined in modules/hal/stm32/dts/st/n6/stm32n657x0hxq-pinctrl.dtsi:5148 */
			xspim_p2_dqs0_pn0: xspim_p2_dqs0_pn0 {
				pinmux = < 0x1a09 >;           /* in modules/hal/stm32/dts/st/n6/stm32n657x0hxq-pinctrl.dtsi:5149 */
				slew-rate = "very-high-speed"; /* in modules/hal/stm32/dts/st/n6/stm32n657x0hxq-pinctrl.dtsi:5150 */
				phandle = < 0x22 >;            /* in zephyr/boards/st/nucleo_n657x0_q/nucleo_n657x0_q_common.dtsi:273 */
			};

			/* node '/soc/pin-controller@56020000/xspim_p2_ncs1_pn1' defined in modules/hal/stm32/dts/st/n6/stm32n657x0hxq-pinctrl.dtsi:5153 */
			xspim_p2_ncs1_pn1: xspim_p2_ncs1_pn1 {
				pinmux = < 0x1a29 >;           /* in modules/hal/stm32/dts/st/n6/stm32n657x0hxq-pinctrl.dtsi:5154 */
				slew-rate = "very-high-speed"; /* in modules/hal/stm32/dts/st/n6/stm32n657x0hxq-pinctrl.dtsi:5155 */
				phandle = < 0x21 >;            /* in zephyr/boards/st/nucleo_n657x0_q/nucleo_n657x0_q_common.dtsi:273 */
			};

			/* node '/soc/pin-controller@56020000/xspim_p2_io0_pn2' defined in modules/hal/stm32/dts/st/n6/stm32n657x0hxq-pinctrl.dtsi:5158 */
			xspim_p2_io0_pn2: xspim_p2_io0_pn2 {
				pinmux = < 0x1a49 >;           /* in modules/hal/stm32/dts/st/n6/stm32n657x0hxq-pinctrl.dtsi:5159 */
				slew-rate = "very-high-speed"; /* in modules/hal/stm32/dts/st/n6/stm32n657x0hxq-pinctrl.dtsi:5160 */
				phandle = < 0x24 >;            /* in zephyr/boards/st/nucleo_n657x0_q/nucleo_n657x0_q_common.dtsi:273 */
			};

			/* node '/soc/pin-controller@56020000/xspim_p2_io1_pn3' defined in modules/hal/stm32/dts/st/n6/stm32n657x0hxq-pinctrl.dtsi:5163 */
			xspim_p2_io1_pn3: xspim_p2_io1_pn3 {
				pinmux = < 0x1a69 >;           /* in modules/hal/stm32/dts/st/n6/stm32n657x0hxq-pinctrl.dtsi:5164 */
				slew-rate = "very-high-speed"; /* in modules/hal/stm32/dts/st/n6/stm32n657x0hxq-pinctrl.dtsi:5165 */
				phandle = < 0x25 >;            /* in zephyr/boards/st/nucleo_n657x0_q/nucleo_n657x0_q_common.dtsi:273 */
			};

			/* node '/soc/pin-controller@56020000/xspim_p2_io2_pn4' defined in modules/hal/stm32/dts/st/n6/stm32n657x0hxq-pinctrl.dtsi:5168 */
			xspim_p2_io2_pn4: xspim_p2_io2_pn4 {
				pinmux = < 0x1a89 >;           /* in modules/hal/stm32/dts/st/n6/stm32n657x0hxq-pinctrl.dtsi:5169 */
				slew-rate = "very-high-speed"; /* in modules/hal/stm32/dts/st/n6/stm32n657x0hxq-pinctrl.dtsi:5170 */
				phandle = < 0x26 >;            /* in zephyr/boards/st/nucleo_n657x0_q/nucleo_n657x0_q_common.dtsi:273 */
			};

			/* node '/soc/pin-controller@56020000/xspim_p2_io3_pn5' defined in modules/hal/stm32/dts/st/n6/stm32n657x0hxq-pinctrl.dtsi:5173 */
			xspim_p2_io3_pn5: xspim_p2_io3_pn5 {
				pinmux = < 0x1aa9 >;           /* in modules/hal/stm32/dts/st/n6/stm32n657x0hxq-pinctrl.dtsi:5174 */
				slew-rate = "very-high-speed"; /* in modules/hal/stm32/dts/st/n6/stm32n657x0hxq-pinctrl.dtsi:5175 */
				phandle = < 0x27 >;            /* in zephyr/boards/st/nucleo_n657x0_q/nucleo_n657x0_q_common.dtsi:273 */
			};

			/* node '/soc/pin-controller@56020000/xspim_p2_clk_pn6' defined in modules/hal/stm32/dts/st/n6/stm32n657x0hxq-pinctrl.dtsi:5178 */
			xspim_p2_clk_pn6: xspim_p2_clk_pn6 {
				pinmux = < 0x1ac9 >;           /* in modules/hal/stm32/dts/st/n6/stm32n657x0hxq-pinctrl.dtsi:5179 */
				slew-rate = "very-high-speed"; /* in modules/hal/stm32/dts/st/n6/stm32n657x0hxq-pinctrl.dtsi:5180 */
				phandle = < 0x23 >;            /* in zephyr/boards/st/nucleo_n657x0_q/nucleo_n657x0_q_common.dtsi:273 */
			};

			/* node '/soc/pin-controller@56020000/xspim_p2_io4_pn8' defined in modules/hal/stm32/dts/st/n6/stm32n657x0hxq-pinctrl.dtsi:5188 */
			xspim_p2_io4_pn8: xspim_p2_io4_pn8 {
				pinmux = < 0x1b09 >;           /* in modules/hal/stm32/dts/st/n6/stm32n657x0hxq-pinctrl.dtsi:5189 */
				slew-rate = "very-high-speed"; /* in modules/hal/stm32/dts/st/n6/stm32n657x0hxq-pinctrl.dtsi:5190 */
				phandle = < 0x28 >;            /* in zephyr/boards/st/nucleo_n657x0_q/nucleo_n657x0_q_common.dtsi:273 */
			};

			/* node '/soc/pin-controller@56020000/xspim_p2_io5_pn9' defined in modules/hal/stm32/dts/st/n6/stm32n657x0hxq-pinctrl.dtsi:5193 */
			xspim_p2_io5_pn9: xspim_p2_io5_pn9 {
				pinmux = < 0x1b29 >;           /* in modules/hal/stm32/dts/st/n6/stm32n657x0hxq-pinctrl.dtsi:5194 */
				slew-rate = "very-high-speed"; /* in modules/hal/stm32/dts/st/n6/stm32n657x0hxq-pinctrl.dtsi:5195 */
				phandle = < 0x29 >;            /* in zephyr/boards/st/nucleo_n657x0_q/nucleo_n657x0_q_common.dtsi:273 */
			};

			/* node '/soc/pin-controller@56020000/xspim_p2_io6_pn10' defined in modules/hal/stm32/dts/st/n6/stm32n657x0hxq-pinctrl.dtsi:5198 */
			xspim_p2_io6_pn10: xspim_p2_io6_pn10 {
				pinmux = < 0x1b49 >;           /* in modules/hal/stm32/dts/st/n6/stm32n657x0hxq-pinctrl.dtsi:5199 */
				slew-rate = "very-high-speed"; /* in modules/hal/stm32/dts/st/n6/stm32n657x0hxq-pinctrl.dtsi:5200 */
				phandle = < 0x2a >;            /* in zephyr/boards/st/nucleo_n657x0_q/nucleo_n657x0_q_common.dtsi:273 */
			};

			/* node '/soc/pin-controller@56020000/xspim_p2_io7_pn11' defined in modules/hal/stm32/dts/st/n6/stm32n657x0hxq-pinctrl.dtsi:5203 */
			xspim_p2_io7_pn11: xspim_p2_io7_pn11 {
				pinmux = < 0x1b69 >;           /* in modules/hal/stm32/dts/st/n6/stm32n657x0hxq-pinctrl.dtsi:5204 */
				slew-rate = "very-high-speed"; /* in modules/hal/stm32/dts/st/n6/stm32n657x0hxq-pinctrl.dtsi:5205 */
				phandle = < 0x2b >;            /* in zephyr/boards/st/nucleo_n657x0_q/nucleo_n657x0_q_common.dtsi:273 */
			};
		};

		/* node '/soc/adc@50022000' defined in zephyr/dts/arm/st/n6/stm32n6.dtsi:436 */
		adc1: adc@50022000 {
			compatible = "st,stm32n6-adc",
			             "st,stm32-adc";                              /* in zephyr/dts/arm/st/n6/stm32n6.dtsi:437 */
			reg = < 0x50022000 0x400 >;                               /* in zephyr/dts/arm/st/n6/stm32n6.dtsi:438 */
			interrupts = < 0x2e 0x0 >;                                /* in zephyr/dts/arm/st/n6/stm32n6.dtsi:441 */
			#io-channel-cells = < 0x1 >;                              /* in zephyr/dts/arm/st/n6/stm32n6.dtsi:442 */
			resolutions = < 0x60630c 0x51630c 0x42630c 0x33630c >;    /* in zephyr/dts/arm/st/n6/stm32n6.dtsi:443 */
			sampling-times = < 0x2 0x3 0x7 0xc 0xe 0x2f 0xf7 0x5dc >; /* in zephyr/dts/arm/st/n6/stm32n6.dtsi:447 */
			st,adc-sequencer = "programmable";                        /* in zephyr/dts/arm/st/n6/stm32n6.dtsi:448 */
			st,adc-oversampler = "extended";                          /* in zephyr/dts/arm/st/n6/stm32n6.dtsi:449 */
			st,adc-internal-regulator = "none";                       /* in zephyr/dts/arm/st/n6/stm32n6.dtsi:450 */
			st,adc-has-deep-powerdown;                                /* in zephyr/dts/arm/st/n6/stm32n6.dtsi:451 */
			st,adc-has-channel-preselection;                          /* in zephyr/dts/arm/st/n6/stm32n6.dtsi:452 */
			clocks = < &rcc 0x250 0x20 >,
			         < &rcc 0xb 0x1440144 >;                          /* in zephyr/boards/st/nucleo_n657x0_q/nucleo_n657x0_q_common.dtsi:173 */
			clock-names = "adcx",
			              "adc_ker";                                  /* in zephyr/boards/st/nucleo_n657x0_q/nucleo_n657x0_q_common.dtsi:175 */
			pinctrl-0 = < &adc1_inp10_pa9 &adc1_inp11_pa10 >;         /* in zephyr/boards/st/nucleo_n657x0_q/nucleo_n657x0_q_common.dtsi:176 */
			pinctrl-names = "default";                                /* in zephyr/boards/st/nucleo_n657x0_q/nucleo_n657x0_q_common.dtsi:177 */
			vref-mv = < 0x708 >;                                      /* in zephyr/boards/st/nucleo_n657x0_q/nucleo_n657x0_q_common.dtsi:178 */
			status = "okay";                                          /* in zephyr/boards/st/nucleo_n657x0_q/nucleo_n657x0_q_common.dtsi:179 */
		};

		/* node '/soc/adc@50022100' defined in zephyr/dts/arm/st/n6/stm32n6.dtsi:456 */
		adc2: adc@50022100 {
			compatible = "st,stm32n6-adc",
			             "st,stm32-adc";                              /* in zephyr/dts/arm/st/n6/stm32n6.dtsi:457 */
			reg = < 0x50022100 0x300 >;                               /* in zephyr/dts/arm/st/n6/stm32n6.dtsi:458 */
			clocks = < &rcc 0x250 0x20 >;                             /* in zephyr/dts/arm/st/n6/stm32n6.dtsi:459 */
			clock-names = "adcx";                                     /* in zephyr/dts/arm/st/n6/stm32n6.dtsi:460 */
			interrupts = < 0x2e 0x0 >;                                /* in zephyr/dts/arm/st/n6/stm32n6.dtsi:461 */
			#io-channel-cells = < 0x1 >;                              /* in zephyr/dts/arm/st/n6/stm32n6.dtsi:462 */
			resolutions = < 0x60630c 0x51630c 0x42630c 0x33630c >;    /* in zephyr/dts/arm/st/n6/stm32n6.dtsi:463 */
			sampling-times = < 0x2 0x3 0x7 0xc 0xe 0x2f 0xf7 0x5dc >; /* in zephyr/dts/arm/st/n6/stm32n6.dtsi:467 */
			st,adc-sequencer = "programmable";                        /* in zephyr/dts/arm/st/n6/stm32n6.dtsi:468 */
			st,adc-oversampler = "extended";                          /* in zephyr/dts/arm/st/n6/stm32n6.dtsi:469 */
			st,adc-internal-regulator = "none";                       /* in zephyr/dts/arm/st/n6/stm32n6.dtsi:470 */
			st,adc-has-deep-powerdown;                                /* in zephyr/dts/arm/st/n6/stm32n6.dtsi:471 */
			st,adc-has-channel-preselection;                          /* in zephyr/dts/arm/st/n6/stm32n6.dtsi:472 */
			status = "disabled";                                      /* in zephyr/dts/arm/st/n6/stm32n6.dtsi:473 */
		};

		/* node '/soc/can@5000a000' defined in zephyr/dts/arm/st/n6/stm32n6.dtsi:476 */
		fdcan1: can@5000a000 {
			compatible = "st,stm32h7-fdcan";                       /* in zephyr/dts/arm/st/n6/stm32n6.dtsi:477 */
			reg = < 0x5000a000 0x400 >,
			      < 0x5000c000 0xd54 >;                            /* in zephyr/dts/arm/st/n6/stm32n6.dtsi:478 */
			reg-names = "m_can",
			            "message_ram";                             /* in zephyr/dts/arm/st/n6/stm32n6.dtsi:479 */
			interrupts = < 0xb4 0x0 >,
			             < 0xb5 0x0 >,
			             < 0xba 0x0 >;                             /* in zephyr/dts/arm/st/n6/stm32n6.dtsi:481 */
			interrupt-names = "int0",
			                  "int1",
			                  "calib";                             /* in zephyr/dts/arm/st/n6/stm32n6.dtsi:482 */
			bosch,mram-cfg = < 0x0 0x1c 0x8 0x3 0x3 0x0 0x3 0x3 >; /* in zephyr/dts/arm/st/n6/stm32n6.dtsi:483 */
			clocks = < &rcc 0x268 0x100 >,
			         < &rcc 0xb 0x120014c >;                       /* in zephyr/boards/st/nucleo_n657x0_q/nucleo_n657x0_q_common.dtsi:183 */
			pinctrl-0 = < &fdcan1_rx_pd0 &fdcan1_tx_ph2 >;         /* in zephyr/boards/st/nucleo_n657x0_q/nucleo_n657x0_q_common.dtsi:185 */
			pinctrl-names = "default";                             /* in zephyr/boards/st/nucleo_n657x0_q/nucleo_n657x0_q_common.dtsi:186 */
			status = "okay";                                       /* in zephyr/boards/st/nucleo_n657x0_q/nucleo_n657x0_q_common.dtsi:187 */
		};

		/* node '/soc/can@5000a400' defined in zephyr/dts/arm/st/n6/stm32n6.dtsi:487 */
		fdcan2: can@5000a400 {
			compatible = "st,stm32h7-fdcan";                         /* in zephyr/dts/arm/st/n6/stm32n6.dtsi:488 */
			reg = < 0x5000a400 0x400 >,
			      < 0x5000c000 0x1aa8 >;                             /* in zephyr/dts/arm/st/n6/stm32n6.dtsi:489 */
			reg-names = "m_can",
			            "message_ram";                               /* in zephyr/dts/arm/st/n6/stm32n6.dtsi:490 */
			clocks = < &rcc 0x268 0x100 >;                           /* in zephyr/dts/arm/st/n6/stm32n6.dtsi:491 */
			interrupts = < 0xb6 0x0 >,
			             < 0xb7 0x0 >;                               /* in zephyr/dts/arm/st/n6/stm32n6.dtsi:492 */
			interrupt-names = "int0",
			                  "int1";                                /* in zephyr/dts/arm/st/n6/stm32n6.dtsi:493 */
			bosch,mram-cfg = < 0xd54 0x1c 0x8 0x3 0x3 0x0 0x3 0x3 >; /* in zephyr/dts/arm/st/n6/stm32n6.dtsi:494 */
			status = "disabled";                                     /* in zephyr/dts/arm/st/n6/stm32n6.dtsi:495 */
		};

		/* node '/soc/can@5000e800' defined in zephyr/dts/arm/st/n6/stm32n6.dtsi:498 */
		fdcan3: can@5000e800 {
			compatible = "st,stm32h7-fdcan";                          /* in zephyr/dts/arm/st/n6/stm32n6.dtsi:499 */
			reg = < 0x5000e800 0x400 >,
			      < 0x5000c000 0x2800 >;                              /* in zephyr/dts/arm/st/n6/stm32n6.dtsi:500 */
			reg-names = "m_can",
			            "message_ram";                                /* in zephyr/dts/arm/st/n6/stm32n6.dtsi:501 */
			clocks = < &rcc 0x268 0x100 >;                            /* in zephyr/dts/arm/st/n6/stm32n6.dtsi:502 */
			interrupts = < 0xb8 0x0 >,
			             < 0xb9 0x0 >;                                /* in zephyr/dts/arm/st/n6/stm32n6.dtsi:503 */
			interrupt-names = "int0",
			                  "int1";                                 /* in zephyr/dts/arm/st/n6/stm32n6.dtsi:504 */
			bosch,mram-cfg = < 0x1aa8 0x1c 0x8 0x3 0x3 0x0 0x3 0x3 >; /* in zephyr/dts/arm/st/n6/stm32n6.dtsi:505 */
			status = "disabled";                                      /* in zephyr/dts/arm/st/n6/stm32n6.dtsi:506 */
		};

		/* node '/soc/serial@52001000' defined in zephyr/dts/arm/st/n6/stm32n6.dtsi:509 */
		usart1: serial@52001000 {
			compatible = "st,stm32-usart",
			             "st,stm32-uart";                  /* in zephyr/dts/arm/st/n6/stm32n6.dtsi:510 */
			reg = < 0x52001000 0x400 >;                    /* in zephyr/dts/arm/st/n6/stm32n6.dtsi:511 */
			resets = < &rctl 0x4584 >;                     /* in zephyr/dts/arm/st/n6/stm32n6.dtsi:513 */
			interrupts = < 0x9f 0x0 >;                     /* in zephyr/dts/arm/st/n6/stm32n6.dtsi:514 */
			clocks = < &rcc 0x26c 0x10 >,
			         < &rcc 0xb 0x1400174 >;               /* in zephyr/boards/st/nucleo_n657x0_q/nucleo_n657x0_q_common.dtsi:226 */
			pinctrl-0 = < &usart1_tx_pe5 &usart1_rx_pe6 >; /* in zephyr/boards/st/nucleo_n657x0_q/nucleo_n657x0_q_common.dtsi:228 */
			pinctrl-names = "default";                     /* in zephyr/boards/st/nucleo_n657x0_q/nucleo_n657x0_q_common.dtsi:229 */
			current-speed = < 0x1c200 >;                   /* in zephyr/boards/st/nucleo_n657x0_q/nucleo_n657x0_q_common.dtsi:230 */
			status = "okay";                               /* in zephyr/boards/st/nucleo_n657x0_q/nucleo_n657x0_q_common.dtsi:231 */
		};

		/* node '/soc/serial@50004400' defined in zephyr/dts/arm/st/n6/stm32n6.dtsi:518 */
		usart2: serial@50004400 {
			compatible = "st,stm32-usart",
			             "st,stm32-uart";    /* in zephyr/dts/arm/st/n6/stm32n6.dtsi:519 */
			reg = < 0x50004400 0x400 >;      /* in zephyr/dts/arm/st/n6/stm32n6.dtsi:520 */
			clocks = < &rcc 0x264 0x20000 >; /* in zephyr/dts/arm/st/n6/stm32n6.dtsi:521 */
			resets = < &rctl 0x4491 >;       /* in zephyr/dts/arm/st/n6/stm32n6.dtsi:522 */
			interrupts = < 0xa0 0x0 >;       /* in zephyr/dts/arm/st/n6/stm32n6.dtsi:523 */
			status = "disabled";             /* in zephyr/dts/arm/st/n6/stm32n6.dtsi:524 */
		};

		/* node '/soc/serial@50004800' defined in zephyr/dts/arm/st/n6/stm32n6.dtsi:527 */
		usart3: arduino_serial: serial@50004800 {
			compatible = "st,stm32-usart",
			             "st,stm32-uart";                  /* in zephyr/dts/arm/st/n6/stm32n6.dtsi:528 */
			reg = < 0x50004800 0x400 >;                    /* in zephyr/dts/arm/st/n6/stm32n6.dtsi:529 */
			resets = < &rctl 0x4492 >;                     /* in zephyr/dts/arm/st/n6/stm32n6.dtsi:531 */
			interrupts = < 0xa1 0x0 >;                     /* in zephyr/dts/arm/st/n6/stm32n6.dtsi:532 */
			clocks = < &rcc 0x264 0x40000 >,
			         < &rcc 0xb 0x1480174 >;               /* in zephyr/boards/st/nucleo_n657x0_q/nucleo_n657x0_q_common.dtsi:235 */
			pinctrl-0 = < &usart3_tx_pd8 &usart3_rx_pd9 >; /* in zephyr/boards/st/nucleo_n657x0_q/nucleo_n657x0_q_common.dtsi:237 */
			pinctrl-names = "default";                     /* in zephyr/boards/st/nucleo_n657x0_q/nucleo_n657x0_q_common.dtsi:238 */
			current-speed = < 0x1c200 >;                   /* in zephyr/boards/st/nucleo_n657x0_q/nucleo_n657x0_q_common.dtsi:239 */
			status = "okay";                               /* in zephyr/boards/st/nucleo_n657x0_q/nucleo_n657x0_q_common.dtsi:240 */
		};

		/* node '/soc/serial@50004c00' defined in zephyr/dts/arm/st/n6/stm32n6.dtsi:536 */
		uart4: serial@50004c00 {
			compatible = "st,stm32-usart",
			             "st,stm32-uart";    /* in zephyr/dts/arm/st/n6/stm32n6.dtsi:537 */
			reg = < 0x50004c00 0x400 >;      /* in zephyr/dts/arm/st/n6/stm32n6.dtsi:538 */
			clocks = < &rcc 0x264 0x80000 >; /* in zephyr/dts/arm/st/n6/stm32n6.dtsi:539 */
			resets = < &rctl 0x4493 >;       /* in zephyr/dts/arm/st/n6/stm32n6.dtsi:540 */
			interrupts = < 0xa2 0x0 >;       /* in zephyr/dts/arm/st/n6/stm32n6.dtsi:541 */
			status = "disabled";             /* in zephyr/dts/arm/st/n6/stm32n6.dtsi:542 */
		};

		/* node '/soc/serial@50005000' defined in zephyr/dts/arm/st/n6/stm32n6.dtsi:545 */
		uart5: serial@50005000 {
			compatible = "st,stm32-usart",
			             "st,stm32-uart";     /* in zephyr/dts/arm/st/n6/stm32n6.dtsi:546 */
			reg = < 0x50005000 0x400 >;       /* in zephyr/dts/arm/st/n6/stm32n6.dtsi:547 */
			clocks = < &rcc 0x264 0x100000 >; /* in zephyr/dts/arm/st/n6/stm32n6.dtsi:548 */
			resets = < &rctl 0x4494 >;        /* in zephyr/dts/arm/st/n6/stm32n6.dtsi:549 */
			interrupts = < 0xa3 0x0 >;        /* in zephyr/dts/arm/st/n6/stm32n6.dtsi:550 */
			status = "disabled";              /* in zephyr/dts/arm/st/n6/stm32n6.dtsi:551 */
		};

		/* node '/soc/serial@52001400' defined in zephyr/dts/arm/st/n6/stm32n6.dtsi:554 */
		usart6: serial@52001400 {
			compatible = "st,stm32-usart",
			             "st,stm32-uart";  /* in zephyr/dts/arm/st/n6/stm32n6.dtsi:555 */
			reg = < 0x52001400 0x400 >;    /* in zephyr/dts/arm/st/n6/stm32n6.dtsi:556 */
			clocks = < &rcc 0x26c 0x20 >;  /* in zephyr/dts/arm/st/n6/stm32n6.dtsi:557 */
			resets = < &rctl 0x4585 >;     /* in zephyr/dts/arm/st/n6/stm32n6.dtsi:558 */
			interrupts = < 0xa4 0x0 >;     /* in zephyr/dts/arm/st/n6/stm32n6.dtsi:559 */
			status = "disabled";           /* in zephyr/dts/arm/st/n6/stm32n6.dtsi:560 */
		};

		/* node '/soc/serial@50007800' defined in zephyr/dts/arm/st/n6/stm32n6.dtsi:563 */
		uart7: serial@50007800 {
			compatible = "st,stm32-usart",
			             "st,stm32-uart";       /* in zephyr/dts/arm/st/n6/stm32n6.dtsi:564 */
			reg = < 0x50007800 0x400 >;         /* in zephyr/dts/arm/st/n6/stm32n6.dtsi:565 */
			clocks = < &rcc 0x264 0x40000000 >; /* in zephyr/dts/arm/st/n6/stm32n6.dtsi:566 */
			resets = < &rctl 0x449e >;          /* in zephyr/dts/arm/st/n6/stm32n6.dtsi:567 */
			interrupts = < 0xa5 0x0 >;          /* in zephyr/dts/arm/st/n6/stm32n6.dtsi:568 */
			status = "disabled";                /* in zephyr/dts/arm/st/n6/stm32n6.dtsi:569 */
		};

		/* node '/soc/serial@50007c00' defined in zephyr/dts/arm/st/n6/stm32n6.dtsi:572 */
		uart8: serial@50007c00 {
			compatible = "st,stm32-usart",
			             "st,stm32-uart";       /* in zephyr/dts/arm/st/n6/stm32n6.dtsi:573 */
			reg = < 0x50007c00 0x400 >;         /* in zephyr/dts/arm/st/n6/stm32n6.dtsi:574 */
			clocks = < &rcc 0x264 0x80000000 >; /* in zephyr/dts/arm/st/n6/stm32n6.dtsi:575 */
			resets = < &rctl 0x449f >;          /* in zephyr/dts/arm/st/n6/stm32n6.dtsi:576 */
			interrupts = < 0xa6 0x0 >;          /* in zephyr/dts/arm/st/n6/stm32n6.dtsi:577 */
			status = "disabled";                /* in zephyr/dts/arm/st/n6/stm32n6.dtsi:578 */
		};

		/* node '/soc/serial@52001800' defined in zephyr/dts/arm/st/n6/stm32n6.dtsi:581 */
		uart9: serial@52001800 {
			compatible = "st,stm32-usart",
			             "st,stm32-uart";  /* in zephyr/dts/arm/st/n6/stm32n6.dtsi:582 */
			reg = < 0x52001800 0x400 >;    /* in zephyr/dts/arm/st/n6/stm32n6.dtsi:583 */
			clocks = < &rcc 0x26c 0x40 >;  /* in zephyr/dts/arm/st/n6/stm32n6.dtsi:584 */
			resets = < &rctl 0x4586 >;     /* in zephyr/dts/arm/st/n6/stm32n6.dtsi:585 */
			interrupts = < 0xa7 0x0 >;     /* in zephyr/dts/arm/st/n6/stm32n6.dtsi:586 */
			status = "disabled";           /* in zephyr/dts/arm/st/n6/stm32n6.dtsi:587 */
		};

		/* node '/soc/serial@52001c00' defined in zephyr/dts/arm/st/n6/stm32n6.dtsi:590 */
		usart10: serial@52001c00 {
			compatible = "st,stm32-usart",
			             "st,stm32-uart";  /* in zephyr/dts/arm/st/n6/stm32n6.dtsi:591 */
			reg = < 0x52001c00 0x400 >;    /* in zephyr/dts/arm/st/n6/stm32n6.dtsi:592 */
			clocks = < &rcc 0x26c 0x80 >;  /* in zephyr/dts/arm/st/n6/stm32n6.dtsi:593 */
			resets = < &rctl 0x4587 >;     /* in zephyr/dts/arm/st/n6/stm32n6.dtsi:594 */
			interrupts = < 0xa8 0x0 >;     /* in zephyr/dts/arm/st/n6/stm32n6.dtsi:595 */
			status = "disabled";           /* in zephyr/dts/arm/st/n6/stm32n6.dtsi:596 */
		};

		/* node '/soc/i2c@50005400' defined in zephyr/dts/arm/st/n6/stm32n6.dtsi:599 */
		i2c1: arduino_i2c: i2c@50005400 {
			compatible = "st,stm32-i2c-v2";              /* in zephyr/dts/arm/st/n6/stm32n6.dtsi:600 */
			#address-cells = < 0x1 >;                    /* in zephyr/dts/arm/st/n6/stm32n6.dtsi:602 */
			#size-cells = < 0x0 >;                       /* in zephyr/dts/arm/st/n6/stm32n6.dtsi:603 */
			reg = < 0x50005400 0x400 >;                  /* in zephyr/dts/arm/st/n6/stm32n6.dtsi:604 */
			interrupts = < 0x64 0x0 >,
			             < 0x65 0x0 >;                   /* in zephyr/dts/arm/st/n6/stm32n6.dtsi:606 */
			interrupt-names = "event",
			                  "error";                   /* in zephyr/dts/arm/st/n6/stm32n6.dtsi:607 */
			clocks = < &rcc 0x264 0x200000 >,
			         < &rcc 0xb 0x1400150 >;             /* in zephyr/boards/st/nucleo_n657x0_q/nucleo_n657x0_q_common.dtsi:191 */
			pinctrl-0 = < &i2c1_scl_ph9 &i2c1_sda_pc1 >; /* in zephyr/boards/st/nucleo_n657x0_q/nucleo_n657x0_q_common.dtsi:193 */
			pinctrl-names = "default";                   /* in zephyr/boards/st/nucleo_n657x0_q/nucleo_n657x0_q_common.dtsi:194 */
			clock-frequency = < 0x186a0 >;               /* in zephyr/boards/st/nucleo_n657x0_q/nucleo_n657x0_q_common.dtsi:195 */
			status = "okay";                             /* in zephyr/boards/st/nucleo_n657x0_q/nucleo_n657x0_q_common.dtsi:196 */
		};

		/* node '/soc/i2c@50005800' defined in zephyr/dts/arm/st/n6/stm32n6.dtsi:611 */
		i2c2: csi_i2c: i2c@50005800 {
			compatible = "st,stm32-i2c-v2";                /* in zephyr/dts/arm/st/n6/stm32n6.dtsi:612 */
			#address-cells = < 0x1 >;                      /* in zephyr/dts/arm/st/n6/stm32n6.dtsi:614 */
			#size-cells = < 0x0 >;                         /* in zephyr/dts/arm/st/n6/stm32n6.dtsi:615 */
			reg = < 0x50005800 0x400 >;                    /* in zephyr/dts/arm/st/n6/stm32n6.dtsi:616 */
			interrupts = < 0x66 0x0 >,
			             < 0x67 0x0 >;                     /* in zephyr/dts/arm/st/n6/stm32n6.dtsi:618 */
			interrupt-names = "event",
			                  "error";                     /* in zephyr/dts/arm/st/n6/stm32n6.dtsi:619 */
			clocks = < &rcc 0x264 0x400000 >,
			         < &rcc 0xb 0x1440150 >;               /* in zephyr/boards/st/nucleo_n657x0_q/nucleo_n657x0_q_common.dtsi:200 */
			pinctrl-0 = < &i2c2_scl_pb10 &i2c2_sda_pb11 >; /* in zephyr/boards/st/nucleo_n657x0_q/nucleo_n657x0_q_common.dtsi:202 */
			pinctrl-names = "default";                     /* in zephyr/boards/st/nucleo_n657x0_q/nucleo_n657x0_q_common.dtsi:203 */
			clock-frequency = < 0x186a0 >;                 /* in zephyr/boards/st/nucleo_n657x0_q/nucleo_n657x0_q_common.dtsi:204 */
			status = "okay";                               /* in zephyr/boards/st/nucleo_n657x0_q/nucleo_n657x0_q_common.dtsi:205 */
		};

		/* node '/soc/i2c@50005c00' defined in zephyr/dts/arm/st/n6/stm32n6.dtsi:623 */
		i2c3: i2c@50005c00 {
			compatible = "st,stm32-i2c-v2";   /* in zephyr/dts/arm/st/n6/stm32n6.dtsi:624 */
			clock-frequency = < 0x186a0 >;    /* in zephyr/dts/arm/st/n6/stm32n6.dtsi:625 */
			#address-cells = < 0x1 >;         /* in zephyr/dts/arm/st/n6/stm32n6.dtsi:626 */
			#size-cells = < 0x0 >;            /* in zephyr/dts/arm/st/n6/stm32n6.dtsi:627 */
			reg = < 0x50005c00 0x400 >;       /* in zephyr/dts/arm/st/n6/stm32n6.dtsi:628 */
			clocks = < &rcc 0x264 0x800000 >; /* in zephyr/dts/arm/st/n6/stm32n6.dtsi:629 */
			interrupts = < 0x68 0x0 >,
			             < 0x69 0x0 >;        /* in zephyr/dts/arm/st/n6/stm32n6.dtsi:630 */
			interrupt-names = "event",
			                  "error";        /* in zephyr/dts/arm/st/n6/stm32n6.dtsi:631 */
			status = "disabled";              /* in zephyr/dts/arm/st/n6/stm32n6.dtsi:632 */
		};

		/* node '/soc/i2c@56001c00' defined in zephyr/dts/arm/st/n6/stm32n6.dtsi:635 */
		i2c4: i2c@56001c00 {
			compatible = "st,stm32-i2c-v2";                /* in zephyr/dts/arm/st/n6/stm32n6.dtsi:636 */
			#address-cells = < 0x1 >;                      /* in zephyr/dts/arm/st/n6/stm32n6.dtsi:638 */
			#size-cells = < 0x0 >;                         /* in zephyr/dts/arm/st/n6/stm32n6.dtsi:639 */
			reg = < 0x56001c00 0x400 >;                    /* in zephyr/dts/arm/st/n6/stm32n6.dtsi:640 */
			interrupts = < 0x6a 0x0 >,
			             < 0x6b 0x0 >;                     /* in zephyr/dts/arm/st/n6/stm32n6.dtsi:642 */
			interrupt-names = "event",
			                  "error";                     /* in zephyr/dts/arm/st/n6/stm32n6.dtsi:643 */
			clocks = < &rcc 0x274 0x80 >,
			         < &rcc 0xb 0x14c0150 >;               /* in zephyr/boards/st/nucleo_n657x0_q/nucleo_n657x0_q_common.dtsi:209 */
			pinctrl-0 = < &i2c4_scl_pe13 &i2c4_sda_pe14 >; /* in zephyr/boards/st/nucleo_n657x0_q/nucleo_n657x0_q_common.dtsi:211 */
			pinctrl-names = "default";                     /* in zephyr/boards/st/nucleo_n657x0_q/nucleo_n657x0_q_common.dtsi:212 */
			clock-frequency = < 0x186a0 >;                 /* in zephyr/boards/st/nucleo_n657x0_q/nucleo_n657x0_q_common.dtsi:213 */
			status = "okay";                               /* in zephyr/boards/st/nucleo_n657x0_q/nucleo_n657x0_q_common.dtsi:214 */
		};

		/* node '/soc/i3c@50006000' defined in zephyr/dts/arm/st/n6/stm32n6.dtsi:647 */
		i3c1: i3c@50006000 {
			compatible = "st,stm32-i3c";       /* in zephyr/dts/arm/st/n6/stm32n6.dtsi:648 */
			reg = < 0x50006000 0x400 >;        /* in zephyr/dts/arm/st/n6/stm32n6.dtsi:649 */
			interrupts = < 0x6c 0x0 >,
			             < 0x6d 0x0 >;         /* in zephyr/dts/arm/st/n6/stm32n6.dtsi:650 */
			interrupt-names = "event",
			                  "error";         /* in zephyr/dts/arm/st/n6/stm32n6.dtsi:651 */
			#address-cells = < 0x3 >;          /* in zephyr/dts/arm/st/n6/stm32n6.dtsi:652 */
			#size-cells = < 0x0 >;             /* in zephyr/dts/arm/st/n6/stm32n6.dtsi:653 */
			clocks = < &rcc 0x264 0x1000000 >; /* in zephyr/dts/arm/st/n6/stm32n6.dtsi:654 */
			resets = < &rctl 0x4498 >;         /* in zephyr/dts/arm/st/n6/stm32n6.dtsi:655 */
			zephyr,pm-device-runtime-auto;     /* in zephyr/dts/arm/st/n6/stm32n6.dtsi:656 */
			status = "disabled";               /* in zephyr/dts/arm/st/n6/stm32n6.dtsi:657 */
		};

		/* node '/soc/i3c@50006400' defined in zephyr/dts/arm/st/n6/stm32n6.dtsi:660 */
		i3c2: i3c@50006400 {
			compatible = "st,stm32-i3c";       /* in zephyr/dts/arm/st/n6/stm32n6.dtsi:661 */
			reg = < 0x50006400 0x400 >;        /* in zephyr/dts/arm/st/n6/stm32n6.dtsi:662 */
			interrupts = < 0x6e 0x0 >,
			             < 0x6f 0x0 >;         /* in zephyr/dts/arm/st/n6/stm32n6.dtsi:663 */
			interrupt-names = "event",
			                  "error";         /* in zephyr/dts/arm/st/n6/stm32n6.dtsi:664 */
			#address-cells = < 0x3 >;          /* in zephyr/dts/arm/st/n6/stm32n6.dtsi:665 */
			#size-cells = < 0x0 >;             /* in zephyr/dts/arm/st/n6/stm32n6.dtsi:666 */
			clocks = < &rcc 0x264 0x2000000 >; /* in zephyr/dts/arm/st/n6/stm32n6.dtsi:667 */
			resets = < &rctl 0x4499 >;         /* in zephyr/dts/arm/st/n6/stm32n6.dtsi:668 */
			zephyr,pm-device-runtime-auto;     /* in zephyr/dts/arm/st/n6/stm32n6.dtsi:669 */
			status = "disabled";               /* in zephyr/dts/arm/st/n6/stm32n6.dtsi:670 */
		};

		/* node '/soc/spi@52003000' defined in zephyr/dts/arm/st/n6/stm32n6.dtsi:673 */
		spi1: spi@52003000 {
			compatible = "st,stm32h7-spi",
			             "st,stm32-spi-fifo",
			             "st,stm32-spi";      /* in zephyr/dts/arm/st/n6/stm32n6.dtsi:674 */
			#address-cells = < 0x1 >;         /* in zephyr/dts/arm/st/n6/stm32n6.dtsi:675 */
			#size-cells = < 0x0 >;            /* in zephyr/dts/arm/st/n6/stm32n6.dtsi:676 */
			reg = < 0x52003000 0x400 >;       /* in zephyr/dts/arm/st/n6/stm32n6.dtsi:677 */
			interrupts = < 0x99 0x0 >;        /* in zephyr/dts/arm/st/n6/stm32n6.dtsi:678 */
			clocks = < &rcc 0x26c 0x1000 >;   /* in zephyr/dts/arm/st/n6/stm32n6.dtsi:679 */
			status = "disabled";              /* in zephyr/dts/arm/st/n6/stm32n6.dtsi:680 */
		};

		/* node '/soc/spi@50003800' defined in zephyr/dts/arm/st/n6/stm32n6.dtsi:683 */
		spi2: spi@50003800 {
			compatible = "st,stm32h7-spi",
			             "st,stm32-spi-fifo",
			             "st,stm32-spi";      /* in zephyr/dts/arm/st/n6/stm32n6.dtsi:684 */
			#address-cells = < 0x1 >;         /* in zephyr/dts/arm/st/n6/stm32n6.dtsi:685 */
			#size-cells = < 0x0 >;            /* in zephyr/dts/arm/st/n6/stm32n6.dtsi:686 */
			reg = < 0x50003800 0x400 >;       /* in zephyr/dts/arm/st/n6/stm32n6.dtsi:687 */
			interrupts = < 0x9a 0x0 >;        /* in zephyr/dts/arm/st/n6/stm32n6.dtsi:688 */
			clocks = < &rcc 0x264 0x4000 >;   /* in zephyr/dts/arm/st/n6/stm32n6.dtsi:689 */
			status = "disabled";              /* in zephyr/dts/arm/st/n6/stm32n6.dtsi:690 */
		};

		/* node '/soc/spi@50003c00' defined in zephyr/dts/arm/st/n6/stm32n6.dtsi:693 */
		spi3: spi@50003c00 {
			compatible = "st,stm32h7-spi",
			             "st,stm32-spi-fifo",
			             "st,stm32-spi";      /* in zephyr/dts/arm/st/n6/stm32n6.dtsi:694 */
			#address-cells = < 0x1 >;         /* in zephyr/dts/arm/st/n6/stm32n6.dtsi:695 */
			#size-cells = < 0x0 >;            /* in zephyr/dts/arm/st/n6/stm32n6.dtsi:696 */
			reg = < 0x50003c00 0x400 >;       /* in zephyr/dts/arm/st/n6/stm32n6.dtsi:697 */
			interrupts = < 0x9b 0x0 >;        /* in zephyr/dts/arm/st/n6/stm32n6.dtsi:698 */
			clocks = < &rcc 0x264 0x8000 >;   /* in zephyr/dts/arm/st/n6/stm32n6.dtsi:699 */
			status = "disabled";              /* in zephyr/dts/arm/st/n6/stm32n6.dtsi:700 */
		};

		/* node '/soc/spi@52003400' defined in zephyr/dts/arm/st/n6/stm32n6.dtsi:703 */
		spi4: spi@52003400 {
			compatible = "st,stm32h7-spi",
			             "st,stm32-spi-fifo",
			             "st,stm32-spi";      /* in zephyr/dts/arm/st/n6/stm32n6.dtsi:704 */
			#address-cells = < 0x1 >;         /* in zephyr/dts/arm/st/n6/stm32n6.dtsi:705 */
			#size-cells = < 0x0 >;            /* in zephyr/dts/arm/st/n6/stm32n6.dtsi:706 */
			reg = < 0x52003400 0x400 >;       /* in zephyr/dts/arm/st/n6/stm32n6.dtsi:707 */
			interrupts = < 0x9c 0x0 >;        /* in zephyr/dts/arm/st/n6/stm32n6.dtsi:708 */
			clocks = < &rcc 0x26c 0x2000 >;   /* in zephyr/dts/arm/st/n6/stm32n6.dtsi:709 */
			status = "disabled";              /* in zephyr/dts/arm/st/n6/stm32n6.dtsi:710 */
		};

		/* node '/soc/spi@52005000' defined in zephyr/dts/arm/st/n6/stm32n6.dtsi:713 */
		spi5: arduino_spi: spi@52005000 {
			compatible = "st,stm32h7-spi",
			             "st,stm32-spi-fifo",
			             "st,stm32-spi";                                                /* in zephyr/dts/arm/st/n6/stm32n6.dtsi:714 */
			#address-cells = < 0x1 >;                                                   /* in zephyr/dts/arm/st/n6/stm32n6.dtsi:715 */
			#size-cells = < 0x0 >;                                                      /* in zephyr/dts/arm/st/n6/stm32n6.dtsi:716 */
			reg = < 0x52005000 0x400 >;                                                 /* in zephyr/dts/arm/st/n6/stm32n6.dtsi:717 */
			interrupts = < 0x9d 0x0 >;                                                  /* in zephyr/dts/arm/st/n6/stm32n6.dtsi:718 */
			clocks = < &rcc 0x26c 0x100000 >,
			         < &rcc 0xb 0x1540164 >;                                            /* in zephyr/boards/st/nucleo_n657x0_q/nucleo_n657x0_q_common.dtsi:218 */
			pinctrl-0 = < &spi5_nss_pa3 &spi5_sck_pe15 &spi5_miso_pg1 &spi5_mosi_pg2 >; /* in zephyr/boards/st/nucleo_n657x0_q/nucleo_n657x0_q_common.dtsi:220 */
			pinctrl-names = "default";                                                  /* in zephyr/boards/st/nucleo_n657x0_q/nucleo_n657x0_q_common.dtsi:221 */
			status = "okay";                                                            /* in zephyr/boards/st/nucleo_n657x0_q/nucleo_n657x0_q_common.dtsi:222 */
		};

		/* node '/soc/spi@56001400' defined in zephyr/dts/arm/st/n6/stm32n6.dtsi:723 */
		spi6: spi@56001400 {
			compatible = "st,stm32h7-spi",
			             "st,stm32-spi-fifo",
			             "st,stm32-spi";      /* in zephyr/dts/arm/st/n6/stm32n6.dtsi:724 */
			#address-cells = < 0x1 >;         /* in zephyr/dts/arm/st/n6/stm32n6.dtsi:725 */
			#size-cells = < 0x0 >;            /* in zephyr/dts/arm/st/n6/stm32n6.dtsi:726 */
			reg = < 0x56001400 0x400 >;       /* in zephyr/dts/arm/st/n6/stm32n6.dtsi:727 */
			interrupts = < 0x9e 0x0 >;        /* in zephyr/dts/arm/st/n6/stm32n6.dtsi:728 */
			clocks = < &rcc 0x274 0x20 >;     /* in zephyr/dts/arm/st/n6/stm32n6.dtsi:729 */
			status = "disabled";              /* in zephyr/dts/arm/st/n6/stm32n6.dtsi:730 */
		};

		/* node '/soc/dma@50021000' defined in zephyr/dts/arm/st/n6/stm32n6.dtsi:733 */
		gpdma1: dma@50021000 {
			compatible = "st,stm32u5-dma";                                                                  /* in zephyr/dts/arm/st/n6/stm32n6.dtsi:734 */
			#dma-cells = < 0x3 >;                                                                           /* in zephyr/dts/arm/st/n6/stm32n6.dtsi:735 */
			reg = < 0x50021000 0x1000 >;                                                                    /* in zephyr/dts/arm/st/n6/stm32n6.dtsi:736 */
			clocks = < &rcc 0x250 0x10 >;                                                                   /* in zephyr/dts/arm/st/n6/stm32n6.dtsi:737 */
			interrupts = < 0x54 0x0 0x55 0x0 0x56 0x0 0x57 0x0 0x58 0x0 0x59 0x0 0x5a 0x0 0x5b 0x0 0x5c 0x0
			               0x5d 0x0 0x5e 0x0 0x5f 0x0 0x60 0x0 0x61 0x0 0x62 0x0 0x63 0x0 >;                /* in zephyr/dts/arm/st/n6/stm32n6.dtsi:738 */
			dma-channels = < 0x10 >;                                                                        /* in zephyr/dts/arm/st/n6/stm32n6.dtsi:740 */
			dma-requests = < 0x90 >;                                                                        /* in zephyr/dts/arm/st/n6/stm32n6.dtsi:741 */
			dma-offset = < 0x0 >;                                                                           /* in zephyr/dts/arm/st/n6/stm32n6.dtsi:742 */
			status = "disabled";                                                                            /* in zephyr/dts/arm/st/n6/stm32n6.dtsi:743 */
			phandle = < 0x2d >;                                                                             /* in zephyr/dts/arm/st/n6/stm32n6.dtsi:1266 */
		};

		/* node '/soc/dcmipp@58002000' defined in zephyr/dts/arm/st/n6/stm32n6.dtsi:746 */
		dcmipp: csi_interface: dcmipp@58002000 {
			compatible = "st,stm32n6-dcmipp",
			             "st,stm32-dcmipp";   /* in zephyr/dts/arm/st/n6/stm32n6.dtsi:747 */
			reg = < 0x58002000 0x1000 >;      /* in zephyr/dts/arm/st/n6/stm32n6.dtsi:748 */
			clock-names = "dcmipp",
			              "dcmipp-ker",
			              "csi";              /* in zephyr/dts/arm/st/n6/stm32n6.dtsi:749 */
			clocks = < &rcc 0x27c 0x4 >,
			         < &rcc 0x1c 0x2340144 >,
			         < &rcc 0x27c 0x40 >;     /* in zephyr/dts/arm/st/n6/stm32n6.dtsi:750 */
			interrupts = < 0x30 0x0 >;        /* in zephyr/dts/arm/st/n6/stm32n6.dtsi:753 */
			resets = < &rctl 0x4782 >,
			         < &rctl 0x4786 >;        /* in zephyr/dts/arm/st/n6/stm32n6.dtsi:754 */
			status = "disabled";              /* in zephyr/dts/arm/st/n6/stm32n6.dtsi:756 */

			/* node '/soc/dcmipp@58002000/pipes' defined in zephyr/dts/arm/st/n6/stm32n6.dtsi:758 */
			pipes {
				compatible = "st,stm32-dcmipp-pipes"; /* in zephyr/dts/arm/st/n6/stm32n6.dtsi:759 */
				#address-cells = < 0x1 >;             /* in zephyr/dts/arm/st/n6/stm32n6.dtsi:760 */
				#size-cells = < 0x0 >;                /* in zephyr/dts/arm/st/n6/stm32n6.dtsi:761 */

				/* node '/soc/dcmipp@58002000/pipes/pipe@0' defined in zephyr/dts/arm/st/n6/stm32n6.dtsi:763 */
				pipe_dump: pipe@0 {
					reg = < 0x0 >; /* in zephyr/dts/arm/st/n6/stm32n6.dtsi:764 */
				};

				/* node '/soc/dcmipp@58002000/pipes/pipe@1' defined in zephyr/dts/arm/st/n6/stm32n6.dtsi:767 */
				pipe_main: pipe@1 {
					reg = < 0x1 >; /* in zephyr/dts/arm/st/n6/stm32n6.dtsi:768 */
				};

				/* node '/soc/dcmipp@58002000/pipes/pipe@2' defined in zephyr/dts/arm/st/n6/stm32n6.dtsi:771 */
				pipe_aux: pipe@2 {
					reg = < 0x2 >; /* in zephyr/dts/arm/st/n6/stm32n6.dtsi:772 */
				};
			};

			/* node '/soc/dcmipp@58002000/port' defined in zephyr/dts/arm/st/n6/stm32n6.dtsi:776 */
			port {

				/* node '/soc/dcmipp@58002000/port/endpoint' defined in zephyr/dts/arm/st/n6/stm32n6.dtsi:777 */
				csi_ep_in: endpoint {
					remote-endpoint-label = ""; /* in zephyr/dts/arm/st/n6/stm32n6.dtsi:778 */
					bus-type = < 0x4 >;         /* in zephyr/dts/arm/st/n6/stm32n6.dtsi:779 */
				};
			};
		};

		/* node '/soc/ethernet@58036000' defined in zephyr/dts/arm/st/n6/stm32n6.dtsi:784 */
		ethernet@58036000 {
			reg = < 0x58036000 0x8000 >;                 /* in zephyr/dts/arm/st/n6/stm32n6.dtsi:785 */
			compatible = "st,stm32-ethernet-controller"; /* in zephyr/dts/arm/st/n6/stm32n6.dtsi:786 */
			clock-names = "stm-eth";                     /* in zephyr/dts/arm/st/n6/stm32n6.dtsi:787 */
			clocks = < &rcc 0x260 0x400000 >;            /* in zephyr/dts/arm/st/n6/stm32n6.dtsi:788 */

			/* node '/soc/ethernet@58036000/ethernet' defined in zephyr/dts/arm/st/n6/stm32n6.dtsi:790 */
			mac: ethernet {
				compatible = "st,stm32n6-ethernet",
				             "st,stm32h7-ethernet",
				             "st,stm32-ethernet";                                                                     /* in zephyr/dts/arm/st/n6/stm32n6.dtsi:791 */
				interrupts = < 0xb3 0x0 >;                                                                            /* in zephyr/dts/arm/st/n6/stm32n6.dtsi:793 */
				clock-names = "mac-clk-tx",
				              "mac-clk-rx";                                                                           /* in zephyr/dts/arm/st/n6/stm32n6.dtsi:794 */
				clocks = < &rcc 0x260 0x800000 >,
				         < &rcc 0x260 0x1000000 >;                                                                    /* in zephyr/dts/arm/st/n6/stm32n6.dtsi:795 */
				status = "okay";                                                                                      /* in zephyr/boards/st/nucleo_n657x0_q/nucleo_n657x0_q_common.dtsi:248 */
				pinctrl-0 = < &eth1_rmii_ref_clk_pf7 &eth1_rmii_crs_dv_pf10 &eth1_rmii_rxd0_pf14 &eth1_rmii_rxd1_pf15
				              &eth1_rmii_tx_en_pf11 &eth1_rmii_txd0_pf12 &eth1_rmii_txd1_pf13 >;                      /* in zephyr/boards/st/nucleo_n657x0_q/nucleo_n657x0_q_common.dtsi:249 */
				pinctrl-names = "default";                                                                            /* in zephyr/boards/st/nucleo_n657x0_q/nucleo_n657x0_q_common.dtsi:256 */
				phy-connection-type = "rmii";                                                                         /* in zephyr/boards/st/nucleo_n657x0_q/nucleo_n657x0_q_common.dtsi:257 */
				phy-handle = < &eth_phy >;                                                                            /* in zephyr/boards/st/nucleo_n657x0_q/nucleo_n657x0_q_common.dtsi:258 */
			};

			/* node '/soc/ethernet@58036000/mdio' defined in zephyr/dts/arm/st/n6/stm32n6.dtsi:800 */
			mdio: mdio {
				compatible = "st,stm32-mdio";                  /* in zephyr/dts/arm/st/n6/stm32n6.dtsi:801 */
				#address-cells = < 0x1 >;                      /* in zephyr/dts/arm/st/n6/stm32n6.dtsi:802 */
				#size-cells = < 0x0 >;                         /* in zephyr/dts/arm/st/n6/stm32n6.dtsi:803 */
				status = "okay";                               /* in zephyr/boards/st/nucleo_n657x0_q/nucleo_n657x0_q_common.dtsi:262 */
				pinctrl-0 = < &eth1_mdio_pf4 &eth1_mdc_pg11 >; /* in zephyr/boards/st/nucleo_n657x0_q/nucleo_n657x0_q_common.dtsi:263 */
				pinctrl-names = "default";                     /* in zephyr/boards/st/nucleo_n657x0_q/nucleo_n657x0_q_common.dtsi:264 */

				/* node '/soc/ethernet@58036000/mdio/ethernet-phy@0' defined in zephyr/boards/st/nucleo_n657x0_q/nucleo_n657x0_q_common.dtsi:266 */
				eth_phy: ethernet-phy@0 {
					compatible = "ethernet-phy"; /* in zephyr/boards/st/nucleo_n657x0_q/nucleo_n657x0_q_common.dtsi:267 */
					reg = < 0x0 >;               /* in zephyr/boards/st/nucleo_n657x0_q/nucleo_n657x0_q_common.dtsi:268 */
					phandle = < 0x1e >;          /* in zephyr/boards/st/nucleo_n657x0_q/nucleo_n657x0_q_common.dtsi:258 */
				};
			};
		};

		/* node '/soc/sdmmc@58027000' defined in zephyr/dts/arm/st/n6/stm32n6.dtsi:808 */
		sdmmc1: sdmmc@58027000 {
			compatible = "st,stm32-sdmmc"; /* in zephyr/dts/arm/st/n6/stm32n6.dtsi:809 */
			reg = < 0x58027000 0x1000 >;   /* in zephyr/dts/arm/st/n6/stm32n6.dtsi:810 */
			clocks = < &rcc 0x260 0x100 >; /* in zephyr/dts/arm/st/n6/stm32n6.dtsi:811 */
			resets = < &rctl 0x4408 >;     /* in zephyr/dts/arm/st/n6/stm32n6.dtsi:812 */
			interrupts = < 0xae 0x0 >;     /* in zephyr/dts/arm/st/n6/stm32n6.dtsi:813 */
			status = "disabled";           /* in zephyr/dts/arm/st/n6/stm32n6.dtsi:814 */
		};

		/* node '/soc/sdmmc@58026800' defined in zephyr/dts/arm/st/n6/stm32n6.dtsi:817 */
		sdmmc2: sdmmc@58026800 {
			compatible = "st,stm32-sdmmc"; /* in zephyr/dts/arm/st/n6/stm32n6.dtsi:818 */
			reg = < 0x58026800 0x400 >;    /* in zephyr/dts/arm/st/n6/stm32n6.dtsi:819 */
			clocks = < &rcc 0x260 0x80 >;  /* in zephyr/dts/arm/st/n6/stm32n6.dtsi:820 */
			resets = < &rctl 0x4407 >;     /* in zephyr/dts/arm/st/n6/stm32n6.dtsi:821 */
			interrupts = < 0xaf 0x0 >;     /* in zephyr/dts/arm/st/n6/stm32n6.dtsi:822 */
			status = "disabled";           /* in zephyr/dts/arm/st/n6/stm32n6.dtsi:823 */
		};

		/* node '/soc/timers@52000000' defined in zephyr/dts/arm/st/n6/stm32n6.dtsi:826 */
		timers1: timers@52000000 {
			compatible = "st,stm32-timers"; /* in zephyr/dts/arm/st/n6/stm32n6.dtsi:827 */
			reg = < 0x52000000 0x400 >;     /* in zephyr/dts/arm/st/n6/stm32n6.dtsi:828 */
			clocks = < &rcc 0x26c 0x1 >,
			         < &rcc 0x21 0xff >;    /* in zephyr/dts/arm/st/n6/stm32n6.dtsi:829 */
			resets = < &rctl 0x4580 >;      /* in zephyr/dts/arm/st/n6/stm32n6.dtsi:831 */
			interrupts = < 0x70 0x0 >,
			             < 0x71 0x0 >,
			             < 0x72 0x0 >,
			             < 0x73 0x0 >;      /* in zephyr/dts/arm/st/n6/stm32n6.dtsi:832 */
			interrupt-names = "brk",
			                  "up",
			                  "trgcom",
			                  "cc";         /* in zephyr/dts/arm/st/n6/stm32n6.dtsi:833 */
			status = "disabled";            /* in zephyr/dts/arm/st/n6/stm32n6.dtsi:834 */

			/* node '/soc/timers@52000000/pwm' defined in zephyr/dts/arm/st/n6/stm32n6.dtsi:836 */
			pwm {
				compatible = "st,stm32-pwm"; /* in zephyr/dts/arm/st/n6/stm32n6.dtsi:837 */
				status = "disabled";         /* in zephyr/dts/arm/st/n6/stm32n6.dtsi:838 */
				#pwm-cells = < 0x3 >;        /* in zephyr/dts/arm/st/n6/stm32n6.dtsi:839 */
			};
		};

		/* node '/soc/timers@50000000' defined in zephyr/dts/arm/st/n6/stm32n6.dtsi:843 */
		timers2: timers@50000000 {
			compatible = "st,stm32-timers"; /* in zephyr/dts/arm/st/n6/stm32n6.dtsi:844 */
			reg = < 0x50000000 0x400 >;     /* in zephyr/dts/arm/st/n6/stm32n6.dtsi:845 */
			clocks = < &rcc 0x264 0x1 >,
			         < &rcc 0x21 0xff >;    /* in zephyr/dts/arm/st/n6/stm32n6.dtsi:846 */
			resets = < &rctl 0x4480 >;      /* in zephyr/dts/arm/st/n6/stm32n6.dtsi:848 */
			interrupts = < 0x74 0x0 >;      /* in zephyr/dts/arm/st/n6/stm32n6.dtsi:849 */
			interrupt-names = "global";     /* in zephyr/dts/arm/st/n6/stm32n6.dtsi:850 */
			status = "disabled";            /* in zephyr/dts/arm/st/n6/stm32n6.dtsi:851 */

			/* node '/soc/timers@50000000/pwm' defined in zephyr/dts/arm/st/n6/stm32n6.dtsi:853 */
			pwm {
				compatible = "st,stm32-pwm"; /* in zephyr/dts/arm/st/n6/stm32n6.dtsi:854 */
				status = "disabled";         /* in zephyr/dts/arm/st/n6/stm32n6.dtsi:855 */
				#pwm-cells = < 0x3 >;        /* in zephyr/dts/arm/st/n6/stm32n6.dtsi:856 */
			};

			/* node '/soc/timers@50000000/counter' defined in zephyr/dts/arm/st/n6/stm32n6.dtsi:859 */
			counter {
				compatible = "st,stm32-counter"; /* in zephyr/dts/arm/st/n6/stm32n6.dtsi:860 */
				status = "disabled";             /* in zephyr/dts/arm/st/n6/stm32n6.dtsi:861 */
			};
		};

		/* node '/soc/timers@50000400' defined in zephyr/dts/arm/st/n6/stm32n6.dtsi:865 */
		timers3: timers@50000400 {
			compatible = "st,stm32-timers"; /* in zephyr/dts/arm/st/n6/stm32n6.dtsi:866 */
			reg = < 0x50000400 0x400 >;     /* in zephyr/dts/arm/st/n6/stm32n6.dtsi:867 */
			clocks = < &rcc 0x264 0x2 >,
			         < &rcc 0x21 0xff >;    /* in zephyr/dts/arm/st/n6/stm32n6.dtsi:868 */
			resets = < &rctl 0x4481 >;      /* in zephyr/dts/arm/st/n6/stm32n6.dtsi:870 */
			interrupts = < 0x75 0x0 >;      /* in zephyr/dts/arm/st/n6/stm32n6.dtsi:871 */
			interrupt-names = "global";     /* in zephyr/dts/arm/st/n6/stm32n6.dtsi:872 */
			status = "disabled";            /* in zephyr/dts/arm/st/n6/stm32n6.dtsi:873 */

			/* node '/soc/timers@50000400/pwm' defined in zephyr/dts/arm/st/n6/stm32n6.dtsi:875 */
			pwm {
				compatible = "st,stm32-pwm"; /* in zephyr/dts/arm/st/n6/stm32n6.dtsi:876 */
				status = "disabled";         /* in zephyr/dts/arm/st/n6/stm32n6.dtsi:877 */
				#pwm-cells = < 0x3 >;        /* in zephyr/dts/arm/st/n6/stm32n6.dtsi:878 */
			};

			/* node '/soc/timers@50000400/counter' defined in zephyr/dts/arm/st/n6/stm32n6.dtsi:881 */
			counter {
				compatible = "st,stm32-counter"; /* in zephyr/dts/arm/st/n6/stm32n6.dtsi:882 */
				status = "disabled";             /* in zephyr/dts/arm/st/n6/stm32n6.dtsi:883 */
			};
		};

		/* node '/soc/timers@50000800' defined in zephyr/dts/arm/st/n6/stm32n6.dtsi:887 */
		timers4: timers@50000800 {
			compatible = "st,stm32-timers"; /* in zephyr/dts/arm/st/n6/stm32n6.dtsi:888 */
			reg = < 0x50000800 0x400 >;     /* in zephyr/dts/arm/st/n6/stm32n6.dtsi:889 */
			clocks = < &rcc 0x264 0x4 >,
			         < &rcc 0x21 0xff >;    /* in zephyr/dts/arm/st/n6/stm32n6.dtsi:890 */
			resets = < &rctl 0x4482 >;      /* in zephyr/dts/arm/st/n6/stm32n6.dtsi:892 */
			interrupts = < 0x76 0x0 >;      /* in zephyr/dts/arm/st/n6/stm32n6.dtsi:893 */
			interrupt-names = "global";     /* in zephyr/dts/arm/st/n6/stm32n6.dtsi:894 */
			status = "disabled";            /* in zephyr/dts/arm/st/n6/stm32n6.dtsi:895 */

			/* node '/soc/timers@50000800/pwm' defined in zephyr/dts/arm/st/n6/stm32n6.dtsi:897 */
			pwm {
				compatible = "st,stm32-pwm"; /* in zephyr/dts/arm/st/n6/stm32n6.dtsi:898 */
				status = "disabled";         /* in zephyr/dts/arm/st/n6/stm32n6.dtsi:899 */
				#pwm-cells = < 0x3 >;        /* in zephyr/dts/arm/st/n6/stm32n6.dtsi:900 */
			};

			/* node '/soc/timers@50000800/counter' defined in zephyr/dts/arm/st/n6/stm32n6.dtsi:903 */
			counter {
				compatible = "st,stm32-counter"; /* in zephyr/dts/arm/st/n6/stm32n6.dtsi:904 */
				status = "disabled";             /* in zephyr/dts/arm/st/n6/stm32n6.dtsi:905 */
			};
		};

		/* node '/soc/timers@50000c00' defined in zephyr/dts/arm/st/n6/stm32n6.dtsi:909 */
		timers5: timers@50000c00 {
			compatible = "st,stm32-timers"; /* in zephyr/dts/arm/st/n6/stm32n6.dtsi:910 */
			reg = < 0x50000c00 0x400 >;     /* in zephyr/dts/arm/st/n6/stm32n6.dtsi:911 */
			clocks = < &rcc 0x264 0x8 >,
			         < &rcc 0x21 0xff >;    /* in zephyr/dts/arm/st/n6/stm32n6.dtsi:912 */
			resets = < &rctl 0x4483 >;      /* in zephyr/dts/arm/st/n6/stm32n6.dtsi:914 */
			interrupts = < 0x77 0x0 >;      /* in zephyr/dts/arm/st/n6/stm32n6.dtsi:915 */
			interrupt-names = "global";     /* in zephyr/dts/arm/st/n6/stm32n6.dtsi:916 */
			status = "disabled";            /* in zephyr/dts/arm/st/n6/stm32n6.dtsi:917 */

			/* node '/soc/timers@50000c00/pwm' defined in zephyr/dts/arm/st/n6/stm32n6.dtsi:919 */
			pwm {
				compatible = "st,stm32-pwm"; /* in zephyr/dts/arm/st/n6/stm32n6.dtsi:920 */
				status = "disabled";         /* in zephyr/dts/arm/st/n6/stm32n6.dtsi:921 */
				#pwm-cells = < 0x3 >;        /* in zephyr/dts/arm/st/n6/stm32n6.dtsi:922 */
			};

			/* node '/soc/timers@50000c00/counter' defined in zephyr/dts/arm/st/n6/stm32n6.dtsi:925 */
			counter {
				compatible = "st,stm32-counter"; /* in zephyr/dts/arm/st/n6/stm32n6.dtsi:926 */
				status = "disabled";             /* in zephyr/dts/arm/st/n6/stm32n6.dtsi:927 */
			};
		};

		/* node '/soc/timers@50001000' defined in zephyr/dts/arm/st/n6/stm32n6.dtsi:931 */
		timers6: timers@50001000 {
			compatible = "st,stm32-timers"; /* in zephyr/dts/arm/st/n6/stm32n6.dtsi:932 */
			reg = < 0x50001000 0x400 >;     /* in zephyr/dts/arm/st/n6/stm32n6.dtsi:933 */
			clocks = < &rcc 0x264 0x10 >,
			         < &rcc 0x21 0xff >;    /* in zephyr/dts/arm/st/n6/stm32n6.dtsi:934 */
			resets = < &rctl 0x4484 >;      /* in zephyr/dts/arm/st/n6/stm32n6.dtsi:936 */
			interrupts = < 0x78 0x0 >;      /* in zephyr/dts/arm/st/n6/stm32n6.dtsi:937 */
			interrupt-names = "global";     /* in zephyr/dts/arm/st/n6/stm32n6.dtsi:938 */
			status = "disabled";            /* in zephyr/dts/arm/st/n6/stm32n6.dtsi:939 */

			/* node '/soc/timers@50001000/counter' defined in zephyr/dts/arm/st/n6/stm32n6.dtsi:941 */
			counter {
				compatible = "st,stm32-counter"; /* in zephyr/dts/arm/st/n6/stm32n6.dtsi:942 */
				status = "disabled";             /* in zephyr/dts/arm/st/n6/stm32n6.dtsi:943 */
			};
		};

		/* node '/soc/timers@50001400' defined in zephyr/dts/arm/st/n6/stm32n6.dtsi:947 */
		timers7: timers@50001400 {
			compatible = "st,stm32-timers"; /* in zephyr/dts/arm/st/n6/stm32n6.dtsi:948 */
			reg = < 0x50001400 0x400 >;     /* in zephyr/dts/arm/st/n6/stm32n6.dtsi:949 */
			clocks = < &rcc 0x264 0x20 >,
			         < &rcc 0x21 0xff >;    /* in zephyr/dts/arm/st/n6/stm32n6.dtsi:950 */
			resets = < &rctl 0x4485 >;      /* in zephyr/dts/arm/st/n6/stm32n6.dtsi:952 */
			interrupts = < 0x79 0x0 >;      /* in zephyr/dts/arm/st/n6/stm32n6.dtsi:953 */
			interrupt-names = "global";     /* in zephyr/dts/arm/st/n6/stm32n6.dtsi:954 */
			status = "disabled";            /* in zephyr/dts/arm/st/n6/stm32n6.dtsi:955 */

			/* node '/soc/timers@50001400/counter' defined in zephyr/dts/arm/st/n6/stm32n6.dtsi:957 */
			counter {
				compatible = "st,stm32-counter"; /* in zephyr/dts/arm/st/n6/stm32n6.dtsi:958 */
				status = "disabled";             /* in zephyr/dts/arm/st/n6/stm32n6.dtsi:959 */
			};
		};

		/* node '/soc/timers@52000400' defined in zephyr/dts/arm/st/n6/stm32n6.dtsi:963 */
		timers8: timers@52000400 {
			compatible = "st,stm32-timers"; /* in zephyr/dts/arm/st/n6/stm32n6.dtsi:964 */
			reg = < 0x52000400 0x400 >;     /* in zephyr/dts/arm/st/n6/stm32n6.dtsi:965 */
			clocks = < &rcc 0x26c 0x2 >,
			         < &rcc 0x21 0xff >;    /* in zephyr/dts/arm/st/n6/stm32n6.dtsi:966 */
			resets = < &rctl 0x4581 >;      /* in zephyr/dts/arm/st/n6/stm32n6.dtsi:968 */
			interrupts = < 0x7a 0x0 >,
			             < 0x7b 0x0 >,
			             < 0x7c 0x0 >,
			             < 0x7d 0x0 >;      /* in zephyr/dts/arm/st/n6/stm32n6.dtsi:969 */
			interrupt-names = "brk",
			                  "up",
			                  "trgcom",
			                  "cc";         /* in zephyr/dts/arm/st/n6/stm32n6.dtsi:970 */
			status = "disabled";            /* in zephyr/dts/arm/st/n6/stm32n6.dtsi:971 */

			/* node '/soc/timers@52000400/pwm' defined in zephyr/dts/arm/st/n6/stm32n6.dtsi:973 */
			pwm {
				compatible = "st,stm32-pwm"; /* in zephyr/dts/arm/st/n6/stm32n6.dtsi:974 */
				status = "disabled";         /* in zephyr/dts/arm/st/n6/stm32n6.dtsi:975 */
				#pwm-cells = < 0x3 >;        /* in zephyr/dts/arm/st/n6/stm32n6.dtsi:976 */
			};
		};

		/* node '/soc/timers@52004c00' defined in zephyr/dts/arm/st/n6/stm32n6.dtsi:980 */
		timers9: timers@52004c00 {
			compatible = "st,stm32-timers";  /* in zephyr/dts/arm/st/n6/stm32n6.dtsi:981 */
			reg = < 0x52004c00 0x400 >;      /* in zephyr/dts/arm/st/n6/stm32n6.dtsi:982 */
			clocks = < &rcc 0x26c 0x80000 >,
			         < &rcc 0x21 0xff >;     /* in zephyr/dts/arm/st/n6/stm32n6.dtsi:983 */
			resets = < &rctl 0x4593 >;       /* in zephyr/dts/arm/st/n6/stm32n6.dtsi:985 */
			interrupts = < 0x7e 0x0 >;       /* in zephyr/dts/arm/st/n6/stm32n6.dtsi:986 */
			interrupt-names = "global";      /* in zephyr/dts/arm/st/n6/stm32n6.dtsi:987 */
			status = "disabled";             /* in zephyr/dts/arm/st/n6/stm32n6.dtsi:988 */

			/* node '/soc/timers@52004c00/pwm' defined in zephyr/dts/arm/st/n6/stm32n6.dtsi:990 */
			pwm {
				compatible = "st,stm32-pwm"; /* in zephyr/dts/arm/st/n6/stm32n6.dtsi:991 */
				status = "disabled";         /* in zephyr/dts/arm/st/n6/stm32n6.dtsi:992 */
				#pwm-cells = < 0x3 >;        /* in zephyr/dts/arm/st/n6/stm32n6.dtsi:993 */
			};

			/* node '/soc/timers@52004c00/counter' defined in zephyr/dts/arm/st/n6/stm32n6.dtsi:996 */
			counter {
				compatible = "st,stm32-counter"; /* in zephyr/dts/arm/st/n6/stm32n6.dtsi:997 */
				status = "disabled";             /* in zephyr/dts/arm/st/n6/stm32n6.dtsi:998 */
			};
		};

		/* node '/soc/timers@50003000' defined in zephyr/dts/arm/st/n6/stm32n6.dtsi:1002 */
		timers10: timers@50003000 {
			compatible = "st,stm32-timers"; /* in zephyr/dts/arm/st/n6/stm32n6.dtsi:1003 */
			reg = < 0x50003000 0x400 >;     /* in zephyr/dts/arm/st/n6/stm32n6.dtsi:1004 */
			clocks = < &rcc 0x264 0x1000 >,
			         < &rcc 0x21 0xff >;    /* in zephyr/dts/arm/st/n6/stm32n6.dtsi:1005 */
			resets = < &rctl 0x448c >;      /* in zephyr/dts/arm/st/n6/stm32n6.dtsi:1007 */
			interrupts = < 0x7f 0x0 >;      /* in zephyr/dts/arm/st/n6/stm32n6.dtsi:1008 */
			interrupt-names = "global";     /* in zephyr/dts/arm/st/n6/stm32n6.dtsi:1009 */
			status = "disabled";            /* in zephyr/dts/arm/st/n6/stm32n6.dtsi:1010 */

			/* node '/soc/timers@50003000/pwm' defined in zephyr/dts/arm/st/n6/stm32n6.dtsi:1012 */
			pwm {
				compatible = "st,stm32-pwm"; /* in zephyr/dts/arm/st/n6/stm32n6.dtsi:1013 */
				status = "disabled";         /* in zephyr/dts/arm/st/n6/stm32n6.dtsi:1014 */
				#pwm-cells = < 0x3 >;        /* in zephyr/dts/arm/st/n6/stm32n6.dtsi:1015 */
			};

			/* node '/soc/timers@50003000/counter' defined in zephyr/dts/arm/st/n6/stm32n6.dtsi:1018 */
			counter {
				compatible = "st,stm32-counter"; /* in zephyr/dts/arm/st/n6/stm32n6.dtsi:1019 */
				status = "disabled";             /* in zephyr/dts/arm/st/n6/stm32n6.dtsi:1020 */
			};
		};

		/* node '/soc/timers@50003400' defined in zephyr/dts/arm/st/n6/stm32n6.dtsi:1024 */
		timers11: timers@50003400 {
			compatible = "st,stm32-timers"; /* in zephyr/dts/arm/st/n6/stm32n6.dtsi:1025 */
			reg = < 0x50003400 0x400 >;     /* in zephyr/dts/arm/st/n6/stm32n6.dtsi:1026 */
			clocks = < &rcc 0x264 0x2000 >,
			         < &rcc 0x21 0xff >;    /* in zephyr/dts/arm/st/n6/stm32n6.dtsi:1027 */
			resets = < &rctl 0x448d >;      /* in zephyr/dts/arm/st/n6/stm32n6.dtsi:1029 */
			interrupts = < 0x80 0x0 >;      /* in zephyr/dts/arm/st/n6/stm32n6.dtsi:1030 */
			interrupt-names = "global";     /* in zephyr/dts/arm/st/n6/stm32n6.dtsi:1031 */
			status = "disabled";            /* in zephyr/dts/arm/st/n6/stm32n6.dtsi:1032 */

			/* node '/soc/timers@50003400/pwm' defined in zephyr/dts/arm/st/n6/stm32n6.dtsi:1034 */
			pwm {
				compatible = "st,stm32-pwm"; /* in zephyr/dts/arm/st/n6/stm32n6.dtsi:1035 */
				status = "disabled";         /* in zephyr/dts/arm/st/n6/stm32n6.dtsi:1036 */
				#pwm-cells = < 0x3 >;        /* in zephyr/dts/arm/st/n6/stm32n6.dtsi:1037 */
			};

			/* node '/soc/timers@50003400/counter' defined in zephyr/dts/arm/st/n6/stm32n6.dtsi:1040 */
			counter {
				compatible = "st,stm32-counter"; /* in zephyr/dts/arm/st/n6/stm32n6.dtsi:1041 */
				status = "disabled";             /* in zephyr/dts/arm/st/n6/stm32n6.dtsi:1042 */
			};
		};

		/* node '/soc/timers@50001800' defined in zephyr/dts/arm/st/n6/stm32n6.dtsi:1046 */
		timers12: timers@50001800 {
			compatible = "st,stm32-timers"; /* in zephyr/dts/arm/st/n6/stm32n6.dtsi:1047 */
			reg = < 0x50001800 0x400 >;     /* in zephyr/dts/arm/st/n6/stm32n6.dtsi:1048 */
			clocks = < &rcc 0x264 0x40 >,
			         < &rcc 0x21 0xff >;    /* in zephyr/dts/arm/st/n6/stm32n6.dtsi:1049 */
			resets = < &rctl 0x4486 >;      /* in zephyr/dts/arm/st/n6/stm32n6.dtsi:1051 */
			interrupts = < 0x81 0x0 >;      /* in zephyr/dts/arm/st/n6/stm32n6.dtsi:1052 */
			interrupt-names = "global";     /* in zephyr/dts/arm/st/n6/stm32n6.dtsi:1053 */
			status = "disabled";            /* in zephyr/dts/arm/st/n6/stm32n6.dtsi:1054 */

			/* node '/soc/timers@50001800/pwm' defined in zephyr/dts/arm/st/n6/stm32n6.dtsi:1056 */
			pwm {
				compatible = "st,stm32-pwm"; /* in zephyr/dts/arm/st/n6/stm32n6.dtsi:1057 */
				status = "disabled";         /* in zephyr/dts/arm/st/n6/stm32n6.dtsi:1058 */
				#pwm-cells = < 0x3 >;        /* in zephyr/dts/arm/st/n6/stm32n6.dtsi:1059 */
			};

			/* node '/soc/timers@50001800/counter' defined in zephyr/dts/arm/st/n6/stm32n6.dtsi:1062 */
			counter {
				compatible = "st,stm32-counter"; /* in zephyr/dts/arm/st/n6/stm32n6.dtsi:1063 */
				status = "disabled";             /* in zephyr/dts/arm/st/n6/stm32n6.dtsi:1064 */
			};
		};

		/* node '/soc/timers@50001c00' defined in zephyr/dts/arm/st/n6/stm32n6.dtsi:1068 */
		timers13: timers@50001c00 {
			compatible = "st,stm32-timers"; /* in zephyr/dts/arm/st/n6/stm32n6.dtsi:1069 */
			reg = < 0x50001c00 0x400 >;     /* in zephyr/dts/arm/st/n6/stm32n6.dtsi:1070 */
			clocks = < &rcc 0x264 0x80 >,
			         < &rcc 0x21 0xff >;    /* in zephyr/dts/arm/st/n6/stm32n6.dtsi:1071 */
			resets = < &rctl 0x4487 >;      /* in zephyr/dts/arm/st/n6/stm32n6.dtsi:1073 */
			interrupts = < 0x82 0x0 >;      /* in zephyr/dts/arm/st/n6/stm32n6.dtsi:1074 */
			interrupt-names = "global";     /* in zephyr/dts/arm/st/n6/stm32n6.dtsi:1075 */
			status = "disabled";            /* in zephyr/dts/arm/st/n6/stm32n6.dtsi:1076 */

			/* node '/soc/timers@50001c00/pwm' defined in zephyr/dts/arm/st/n6/stm32n6.dtsi:1078 */
			pwm {
				compatible = "st,stm32-pwm"; /* in zephyr/dts/arm/st/n6/stm32n6.dtsi:1079 */
				status = "disabled";         /* in zephyr/dts/arm/st/n6/stm32n6.dtsi:1080 */
				#pwm-cells = < 0x3 >;        /* in zephyr/dts/arm/st/n6/stm32n6.dtsi:1081 */
			};

			/* node '/soc/timers@50001c00/counter' defined in zephyr/dts/arm/st/n6/stm32n6.dtsi:1084 */
			counter {
				compatible = "st,stm32-counter"; /* in zephyr/dts/arm/st/n6/stm32n6.dtsi:1085 */
				status = "disabled";             /* in zephyr/dts/arm/st/n6/stm32n6.dtsi:1086 */
			};
		};

		/* node '/soc/timers@50002000' defined in zephyr/dts/arm/st/n6/stm32n6.dtsi:1090 */
		timers14: timers@50002000 {
			compatible = "st,stm32-timers"; /* in zephyr/dts/arm/st/n6/stm32n6.dtsi:1091 */
			reg = < 0x50002000 0x400 >;     /* in zephyr/dts/arm/st/n6/stm32n6.dtsi:1092 */
			clocks = < &rcc 0x264 0x100 >,
			         < &rcc 0x21 0xff >;    /* in zephyr/dts/arm/st/n6/stm32n6.dtsi:1093 */
			resets = < &rctl 0x4488 >;      /* in zephyr/dts/arm/st/n6/stm32n6.dtsi:1095 */
			interrupts = < 0x83 0x0 >;      /* in zephyr/dts/arm/st/n6/stm32n6.dtsi:1096 */
			interrupt-names = "global";     /* in zephyr/dts/arm/st/n6/stm32n6.dtsi:1097 */
			status = "disabled";            /* in zephyr/dts/arm/st/n6/stm32n6.dtsi:1098 */

			/* node '/soc/timers@50002000/pwm' defined in zephyr/dts/arm/st/n6/stm32n6.dtsi:1100 */
			pwm {
				compatible = "st,stm32-pwm"; /* in zephyr/dts/arm/st/n6/stm32n6.dtsi:1101 */
				status = "disabled";         /* in zephyr/dts/arm/st/n6/stm32n6.dtsi:1102 */
				#pwm-cells = < 0x3 >;        /* in zephyr/dts/arm/st/n6/stm32n6.dtsi:1103 */
			};

			/* node '/soc/timers@50002000/counter' defined in zephyr/dts/arm/st/n6/stm32n6.dtsi:1106 */
			counter {
				compatible = "st,stm32-counter"; /* in zephyr/dts/arm/st/n6/stm32n6.dtsi:1107 */
				status = "disabled";             /* in zephyr/dts/arm/st/n6/stm32n6.dtsi:1108 */
			};
		};

		/* node '/soc/timers@52004000' defined in zephyr/dts/arm/st/n6/stm32n6.dtsi:1112 */
		timers15: timers@52004000 {
			compatible = "st,stm32-timers";  /* in zephyr/dts/arm/st/n6/stm32n6.dtsi:1113 */
			reg = < 0x52004000 0x400 >;      /* in zephyr/dts/arm/st/n6/stm32n6.dtsi:1114 */
			clocks = < &rcc 0x26c 0x10000 >,
			         < &rcc 0x21 0xff >;     /* in zephyr/dts/arm/st/n6/stm32n6.dtsi:1115 */
			resets = < &rctl 0x4590 >;       /* in zephyr/dts/arm/st/n6/stm32n6.dtsi:1117 */
			interrupts = < 0x84 0x0 >;       /* in zephyr/dts/arm/st/n6/stm32n6.dtsi:1118 */
			interrupt-names = "global";      /* in zephyr/dts/arm/st/n6/stm32n6.dtsi:1119 */
			status = "disabled";             /* in zephyr/dts/arm/st/n6/stm32n6.dtsi:1120 */

			/* node '/soc/timers@52004000/pwm' defined in zephyr/dts/arm/st/n6/stm32n6.dtsi:1122 */
			pwm {
				compatible = "st,stm32-pwm"; /* in zephyr/dts/arm/st/n6/stm32n6.dtsi:1123 */
				status = "disabled";         /* in zephyr/dts/arm/st/n6/stm32n6.dtsi:1124 */
				#pwm-cells = < 0x3 >;        /* in zephyr/dts/arm/st/n6/stm32n6.dtsi:1125 */
			};

			/* node '/soc/timers@52004000/counter' defined in zephyr/dts/arm/st/n6/stm32n6.dtsi:1128 */
			counter {
				compatible = "st,stm32-counter"; /* in zephyr/dts/arm/st/n6/stm32n6.dtsi:1129 */
				status = "disabled";             /* in zephyr/dts/arm/st/n6/stm32n6.dtsi:1130 */
			};
		};

		/* node '/soc/timers@52004400' defined in zephyr/dts/arm/st/n6/stm32n6.dtsi:1134 */
		timers16: timers@52004400 {
			compatible = "st,stm32-timers";  /* in zephyr/dts/arm/st/n6/stm32n6.dtsi:1135 */
			reg = < 0x52004400 0x400 >;      /* in zephyr/dts/arm/st/n6/stm32n6.dtsi:1136 */
			clocks = < &rcc 0x26c 0x20000 >,
			         < &rcc 0x21 0xff >;     /* in zephyr/dts/arm/st/n6/stm32n6.dtsi:1137 */
			resets = < &rctl 0x4591 >;       /* in zephyr/dts/arm/st/n6/stm32n6.dtsi:1139 */
			interrupts = < 0x85 0x0 >;       /* in zephyr/dts/arm/st/n6/stm32n6.dtsi:1140 */
			interrupt-names = "global";      /* in zephyr/dts/arm/st/n6/stm32n6.dtsi:1141 */
			status = "disabled";             /* in zephyr/dts/arm/st/n6/stm32n6.dtsi:1142 */

			/* node '/soc/timers@52004400/pwm' defined in zephyr/dts/arm/st/n6/stm32n6.dtsi:1144 */
			pwm {
				compatible = "st,stm32-pwm"; /* in zephyr/dts/arm/st/n6/stm32n6.dtsi:1145 */
				status = "disabled";         /* in zephyr/dts/arm/st/n6/stm32n6.dtsi:1146 */
				#pwm-cells = < 0x3 >;        /* in zephyr/dts/arm/st/n6/stm32n6.dtsi:1147 */
			};

			/* node '/soc/timers@52004400/counter' defined in zephyr/dts/arm/st/n6/stm32n6.dtsi:1150 */
			counter {
				compatible = "st,stm32-counter"; /* in zephyr/dts/arm/st/n6/stm32n6.dtsi:1151 */
				status = "disabled";             /* in zephyr/dts/arm/st/n6/stm32n6.dtsi:1152 */
			};
		};

		/* node '/soc/timers@52004800' defined in zephyr/dts/arm/st/n6/stm32n6.dtsi:1156 */
		timers17: timers@52004800 {
			compatible = "st,stm32-timers";  /* in zephyr/dts/arm/st/n6/stm32n6.dtsi:1157 */
			reg = < 0x52004800 0x400 >;      /* in zephyr/dts/arm/st/n6/stm32n6.dtsi:1158 */
			clocks = < &rcc 0x26c 0x40000 >,
			         < &rcc 0x21 0xff >;     /* in zephyr/dts/arm/st/n6/stm32n6.dtsi:1159 */
			resets = < &rctl 0x4592 >;       /* in zephyr/dts/arm/st/n6/stm32n6.dtsi:1161 */
			interrupts = < 0x86 0x0 >;       /* in zephyr/dts/arm/st/n6/stm32n6.dtsi:1162 */
			interrupt-names = "global";      /* in zephyr/dts/arm/st/n6/stm32n6.dtsi:1163 */
			status = "disabled";             /* in zephyr/dts/arm/st/n6/stm32n6.dtsi:1164 */

			/* node '/soc/timers@52004800/pwm' defined in zephyr/dts/arm/st/n6/stm32n6.dtsi:1166 */
			pwm {
				compatible = "st,stm32-pwm"; /* in zephyr/dts/arm/st/n6/stm32n6.dtsi:1167 */
				status = "disabled";         /* in zephyr/dts/arm/st/n6/stm32n6.dtsi:1168 */
				#pwm-cells = < 0x3 >;        /* in zephyr/dts/arm/st/n6/stm32n6.dtsi:1169 */
			};

			/* node '/soc/timers@52004800/counter' defined in zephyr/dts/arm/st/n6/stm32n6.dtsi:1172 */
			counter {
				compatible = "st,stm32-counter"; /* in zephyr/dts/arm/st/n6/stm32n6.dtsi:1173 */
				status = "disabled";             /* in zephyr/dts/arm/st/n6/stm32n6.dtsi:1174 */
			};
		};

		/* node '/soc/timers@52003c00' defined in zephyr/dts/arm/st/n6/stm32n6.dtsi:1178 */
		timers18: timers@52003c00 {
			compatible = "st,stm32-timers"; /* in zephyr/dts/arm/st/n6/stm32n6.dtsi:1179 */
			reg = < 0x52003c00 0x400 >;     /* in zephyr/dts/arm/st/n6/stm32n6.dtsi:1180 */
			clocks = < &rcc 0x26c 0x8000 >,
			         < &rcc 0x21 0xff >;    /* in zephyr/dts/arm/st/n6/stm32n6.dtsi:1181 */
			resets = < &rctl 0x458f >;      /* in zephyr/dts/arm/st/n6/stm32n6.dtsi:1183 */
			interrupts = < 0x87 0x0 >;      /* in zephyr/dts/arm/st/n6/stm32n6.dtsi:1184 */
			interrupt-names = "global";     /* in zephyr/dts/arm/st/n6/stm32n6.dtsi:1185 */
			status = "disabled";            /* in zephyr/dts/arm/st/n6/stm32n6.dtsi:1186 */

			/* node '/soc/timers@52003c00/counter' defined in zephyr/dts/arm/st/n6/stm32n6.dtsi:1188 */
			counter {
				compatible = "st,stm32-counter"; /* in zephyr/dts/arm/st/n6/stm32n6.dtsi:1189 */
				status = "disabled";             /* in zephyr/dts/arm/st/n6/stm32n6.dtsi:1190 */
			};
		};

		/* node '/soc/xspi@58025000' defined in zephyr/dts/arm/st/n6/stm32n6.dtsi:1194 */
		xspi1: xspi@58025000 {
			compatible = "st,stm32-xspi";    /* in zephyr/dts/arm/st/n6/stm32n6.dtsi:1195 */
			reg = < 0x58025000 0x1000 >,
			      < 0x90000000 0x10000000 >; /* in zephyr/dts/arm/st/n6/stm32n6.dtsi:1196 */
			interrupts = < 0xaa 0x0 >;       /* in zephyr/dts/arm/st/n6/stm32n6.dtsi:1197 */
			clock-names = "xspix",
			              "xspi-ker",
			              "xspi-mgr";        /* in zephyr/dts/arm/st/n6/stm32n6.dtsi:1198 */
			clocks = < &rcc 0x260 0x20 >,
			         < &rcc 0x26 0x200158 >,
			         < &rcc 0x260 0x2000 >;  /* in zephyr/dts/arm/st/n6/stm32n6.dtsi:1199 */
			#address-cells = < 0x1 >;        /* in zephyr/dts/arm/st/n6/stm32n6.dtsi:1202 */
			#size-cells = < 0x0 >;           /* in zephyr/dts/arm/st/n6/stm32n6.dtsi:1203 */
			status = "disabled";             /* in zephyr/dts/arm/st/n6/stm32n6.dtsi:1204 */
		};

		/* node '/soc/spi@5802a000' defined in zephyr/dts/arm/st/n6/stm32n6.dtsi:1207 */
		xspi2: spi@5802a000 {
			compatible = "st,stm32-xspi";                                                                             /* in zephyr/dts/arm/st/n6/stm32n6.dtsi:1208 */
			reg = < 0x5802a000 0x1000 >,
			      < 0x70000000 0x10000000 >;                                                                          /* in zephyr/dts/arm/st/n6/stm32n6.dtsi:1209 */
			interrupts = < 0xab 0x0 >;                                                                                /* in zephyr/dts/arm/st/n6/stm32n6.dtsi:1210 */
			clock-names = "xspix",
			              "xspi-ker",
			              "xspi-mgr";                                                                                 /* in zephyr/dts/arm/st/n6/stm32n6.dtsi:1211 */
			#address-cells = < 0x1 >;                                                                                 /* in zephyr/dts/arm/st/n6/stm32n6.dtsi:1215 */
			#size-cells = < 0x0 >;                                                                                    /* in zephyr/dts/arm/st/n6/stm32n6.dtsi:1216 */
			pinctrl-0 = < &xspim_p2_ncs1_pn1 &xspim_p2_dqs0_pn0 &xspim_p2_clk_pn6 &xspim_p2_io0_pn2 &xspim_p2_io1_pn3
			              &xspim_p2_io2_pn4 &xspim_p2_io3_pn5 &xspim_p2_io4_pn8 &xspim_p2_io5_pn9 &xspim_p2_io6_pn10
			              &xspim_p2_io7_pn11 >;                                                                       /* in zephyr/boards/st/nucleo_n657x0_q/nucleo_n657x0_q_common.dtsi:273 */
			pinctrl-names = "default";                                                                                /* in zephyr/boards/st/nucleo_n657x0_q/nucleo_n657x0_q_common.dtsi:277 */
			clocks = < &rcc 0x260 0x1000 >,
			         < &rcc 0x26 0x240158 >,
			         < &rcc 0x260 0x2000 >;                                                                           /* in zephyr/boards/st/nucleo_n657x0_q/nucleo_n657x0_q_common.dtsi:278 */
			status = "okay";                                                                                          /* in zephyr/boards/st/nucleo_n657x0_q/nucleo_n657x0_q_common.dtsi:281 */

			/* node '/soc/spi@5802a000/ospi-nor-flash@0' defined in zephyr/boards/st/nucleo_n657x0_q/nucleo_n657x0_q_common.dtsi:283 */
			mx25um51245g: ospi-nor-flash@0 {
				compatible = "st,stm32-xspi-nor";   /* in zephyr/boards/st/nucleo_n657x0_q/nucleo_n657x0_q_common.dtsi:284 */
				reg = < 0x0 >;                      /* in zephyr/boards/st/nucleo_n657x0_q/nucleo_n657x0_q_common.dtsi:285 */
				size = < 0x20000000 >;              /* in zephyr/boards/st/nucleo_n657x0_q/nucleo_n657x0_q_common.dtsi:286 */
				ospi-max-frequency = < 0xbebc200 >; /* in zephyr/boards/st/nucleo_n657x0_q/nucleo_n657x0_q_common.dtsi:287 */
				spi-bus-width = < 0x8 >;            /* in zephyr/boards/st/nucleo_n657x0_q/nucleo_n657x0_q_common.dtsi:288 */
				data-rate = < 0x2 >;                /* in zephyr/boards/st/nucleo_n657x0_q/nucleo_n657x0_q_common.dtsi:289 */
				four-byte-opcodes;                  /* in zephyr/boards/st/nucleo_n657x0_q/nucleo_n657x0_q_common.dtsi:290 */
				status = "okay";                    /* in zephyr/boards/st/nucleo_n657x0_q/nucleo_n657x0_q_common.dtsi:291 */

				/* node '/soc/spi@5802a000/ospi-nor-flash@0/partitions' defined in zephyr/boards/st/nucleo_n657x0_q/nucleo_n657x0_q_common.dtsi:293 */
				partitions {
					compatible = "fixed-partitions"; /* in zephyr/boards/st/nucleo_n657x0_q/nucleo_n657x0_q_common.dtsi:294 */
					#address-cells = < 0x1 >;        /* in zephyr/boards/st/nucleo_n657x0_q/nucleo_n657x0_q_common.dtsi:295 */
					#size-cells = < 0x1 >;           /* in zephyr/boards/st/nucleo_n657x0_q/nucleo_n657x0_q_common.dtsi:296 */

					/* node '/soc/spi@5802a000/ospi-nor-flash@0/partitions/partition@3ff0000' defined in zephyr/boards/st/nucleo_n657x0_q/nucleo_n657x0_q_common.dtsi:298 */
					storage_partition: partition@3ff0000 {
						label = "storage";          /* in zephyr/boards/st/nucleo_n657x0_q/nucleo_n657x0_q_common.dtsi:299 */
						reg = < 0x3ff0000 0xffe0 >; /* in zephyr/boards/st/nucleo_n657x0_q/nucleo_n657x0_q_common.dtsi:306 */
					};
				};
			};
		};

		/* node '/soc/otghs@58040000' defined in zephyr/dts/arm/st/n6/stm32n6.dtsi:1220 */
		usbotg_hs1: zephyr_udc0: otghs@58040000 {
			compatible = "st,stm32n6-otghs",
			             "st,stm32-otghs";     /* in zephyr/dts/arm/st/n6/stm32n6.dtsi:1221 */
			reg = < 0x58040000 0x2000 >;       /* in zephyr/dts/arm/st/n6/stm32n6.dtsi:1222 */
			interrupts = < 0xb1 0x0 >;         /* in zephyr/dts/arm/st/n6/stm32n6.dtsi:1223 */
			interrupt-names = "otghs";         /* in zephyr/dts/arm/st/n6/stm32n6.dtsi:1224 */
			num-bidir-endpoints = < 0x9 >;     /* in zephyr/dts/arm/st/n6/stm32n6.dtsi:1225 */
			ram-size = < 0x1000 >;             /* in zephyr/dts/arm/st/n6/stm32n6.dtsi:1226 */
			maximum-speed = "high-speed";      /* in zephyr/dts/arm/st/n6/stm32n6.dtsi:1227 */
			clocks = < &rcc 0x260 0x4000000 >,
			         < &rcc 0x4 0x1100158 >;   /* in zephyr/dts/arm/st/n6/stm32n6.dtsi:1228 */
			phys = < &usbphyc1 >;              /* in zephyr/dts/arm/st/n6/stm32n6.dtsi:1230 */
			status = "okay";                   /* in zephyr/boards/st/nucleo_n657x0_q/nucleo_n657x0_q_common.dtsi:244 */
		};

		/* node '/soc/usbphyc@5803fc00' defined in zephyr/dts/arm/st/n6/stm32n6.dtsi:1234 */
		usbphyc1: usbphyc@5803fc00 {
			compatible = "st,stm32-usbphyc";   /* in zephyr/dts/arm/st/n6/stm32n6.dtsi:1235 */
			reg = < 0x5803fc00 0x400 >;        /* in zephyr/dts/arm/st/n6/stm32n6.dtsi:1236 */
			clocks = < &rcc 0x260 0x8000000 >; /* in zephyr/dts/arm/st/n6/stm32n6.dtsi:1237 */
			#phy-cells = < 0x0 >;              /* in zephyr/dts/arm/st/n6/stm32n6.dtsi:1238 */
			phandle = < 0x2c >;                /* in zephyr/dts/arm/st/n6/stm32n6.dtsi:1230 */
		};

		/* node '/soc/ltdc@58001000' defined in zephyr/dts/arm/st/n6/stm32n6.dtsi:1241 */
		ltdc: ltdc@58001000 {
			compatible = "st,stm32-ltdc";    /* in zephyr/dts/arm/st/n6/stm32n6.dtsi:1242 */
			reg = < 0x58001000 0x1000 >;     /* in zephyr/dts/arm/st/n6/stm32n6.dtsi:1243 */
			interrupts = < 0xc1 0x0 >,
			             < 0xc2 0x0 >;       /* in zephyr/dts/arm/st/n6/stm32n6.dtsi:1244 */
			interrupt-names = "ltdc",
			                  "ltdc_er";     /* in zephyr/dts/arm/st/n6/stm32n6.dtsi:1245 */
			clocks = < &rcc 0x27c 0x2 >,
			         < &rcc 0x2a 0x380150 >; /* in zephyr/dts/arm/st/n6/stm32n6.dtsi:1246 */
			resets = < &rctl 0x4781 >;       /* in zephyr/dts/arm/st/n6/stm32n6.dtsi:1248 */
			status = "disabled";             /* in zephyr/dts/arm/st/n6/stm32n6.dtsi:1249 */
		};

		/* node '/soc/rng@54020000' defined in zephyr/dts/arm/st/n6/stm32n6.dtsi:1252 */
		rng: rng@54020000 {
			compatible = "st,stm32-rng"; /* in zephyr/dts/arm/st/n6/stm32n6.dtsi:1253 */
			reg = < 0x54020000 0x400 >;  /* in zephyr/dts/arm/st/n6/stm32n6.dtsi:1254 */
			interrupts = < 0x28 0x0 >;   /* in zephyr/dts/arm/st/n6/stm32n6.dtsi:1255 */
			clocks = < &rcc 0x258 0x1 >; /* in zephyr/dts/arm/st/n6/stm32n6.dtsi:1256 */
			status = "disabled";         /* in zephyr/dts/arm/st/n6/stm32n6.dtsi:1257 */
		};

		/* node '/soc/sai1@52005804' defined in zephyr/dts/arm/st/n6/stm32n6.dtsi:1260 */
		sai1_a: sai1@52005804 {
			compatible = "st,stm32-sai";         /* in zephyr/dts/arm/st/n6/stm32n6.dtsi:1261 */
			#address-cells = < 0x1 >;            /* in zephyr/dts/arm/st/n6/stm32n6.dtsi:1262 */
			#size-cells = < 0x0 >;               /* in zephyr/dts/arm/st/n6/stm32n6.dtsi:1263 */
			reg = < 0x52005804 0x20 >;           /* in zephyr/dts/arm/st/n6/stm32n6.dtsi:1264 */
			clocks = < &rcc 0x26c 0x200000 >;    /* in zephyr/dts/arm/st/n6/stm32n6.dtsi:1265 */
			dmas = < &gpdma1 0x1 0x5b 0x22800 >; /* in zephyr/dts/arm/st/n6/stm32n6.dtsi:1266 */
			status = "disabled";                 /* in zephyr/dts/arm/st/n6/stm32n6.dtsi:1268 */
		};

		/* node '/soc/sai1@52005824' defined in zephyr/dts/arm/st/n6/stm32n6.dtsi:1271 */
		sai1_b: sai1@52005824 {
			compatible = "st,stm32-sai";         /* in zephyr/dts/arm/st/n6/stm32n6.dtsi:1272 */
			#address-cells = < 0x1 >;            /* in zephyr/dts/arm/st/n6/stm32n6.dtsi:1273 */
			#size-cells = < 0x0 >;               /* in zephyr/dts/arm/st/n6/stm32n6.dtsi:1274 */
			reg = < 0x52005824 0x20 >;           /* in zephyr/dts/arm/st/n6/stm32n6.dtsi:1275 */
			clocks = < &rcc 0x26c 0x200000 >;    /* in zephyr/dts/arm/st/n6/stm32n6.dtsi:1276 */
			dmas = < &gpdma1 0x0 0x5c 0x22800 >; /* in zephyr/dts/arm/st/n6/stm32n6.dtsi:1277 */
			status = "disabled";                 /* in zephyr/dts/arm/st/n6/stm32n6.dtsi:1279 */
		};

		/* node '/soc/sai2@52005c04' defined in zephyr/dts/arm/st/n6/stm32n6.dtsi:1282 */
		sai2_a: sai2@52005c04 {
			compatible = "st,stm32-sai";         /* in zephyr/dts/arm/st/n6/stm32n6.dtsi:1283 */
			#address-cells = < 0x1 >;            /* in zephyr/dts/arm/st/n6/stm32n6.dtsi:1284 */
			#size-cells = < 0x0 >;               /* in zephyr/dts/arm/st/n6/stm32n6.dtsi:1285 */
			reg = < 0x52005c04 0x20 >;           /* in zephyr/dts/arm/st/n6/stm32n6.dtsi:1286 */
			clocks = < &rcc 0x26c 0x400000 >;    /* in zephyr/dts/arm/st/n6/stm32n6.dtsi:1287 */
			dmas = < &gpdma1 0x3 0x5d 0x22800 >; /* in zephyr/dts/arm/st/n6/stm32n6.dtsi:1288 */
			status = "disabled";                 /* in zephyr/dts/arm/st/n6/stm32n6.dtsi:1290 */
		};

		/* node '/soc/sai2@52005c24' defined in zephyr/dts/arm/st/n6/stm32n6.dtsi:1293 */
		sai2_b: sai2@52005c24 {
			compatible = "st,stm32-sai";         /* in zephyr/dts/arm/st/n6/stm32n6.dtsi:1294 */
			#address-cells = < 0x1 >;            /* in zephyr/dts/arm/st/n6/stm32n6.dtsi:1295 */
			#size-cells = < 0x0 >;               /* in zephyr/dts/arm/st/n6/stm32n6.dtsi:1296 */
			reg = < 0x52005c24 0x20 >;           /* in zephyr/dts/arm/st/n6/stm32n6.dtsi:1297 */
			clocks = < &rcc 0x26c 0x400000 >;    /* in zephyr/dts/arm/st/n6/stm32n6.dtsi:1298 */
			dmas = < &gpdma1 0x2 0x5e 0x22800 >; /* in zephyr/dts/arm/st/n6/stm32n6.dtsi:1299 */
			status = "disabled";                 /* in zephyr/dts/arm/st/n6/stm32n6.dtsi:1301 */
		};

		/* node '/soc/npu@580c0000' defined in zephyr/dts/arm/st/n6/stm32n6.dtsi:1304 */
		npu: npu@580c0000 {
			compatible = "st,stm32-npu";        /* in zephyr/dts/arm/st/n6/stm32n6.dtsi:1305 */
			reg = < 0x580c0000 0x1000 >;        /* in zephyr/dts/arm/st/n6/stm32n6.dtsi:1306 */
			clocks = < &rcc 0x260 0x80000000 >,
			         < &rcc 0x260 0x40000000 >; /* in zephyr/dts/arm/st/n6/stm32n6.dtsi:1307 */
			clock-names = "npu",
			              "cacheaxi";           /* in zephyr/dts/arm/st/n6/stm32n6.dtsi:1309 */
			resets = < &rctl 0x441f >,
			         < &rctl 0x441e >;          /* in zephyr/dts/arm/st/n6/stm32n6.dtsi:1310 */
			status = "disabled";                /* in zephyr/dts/arm/st/n6/stm32n6.dtsi:1312 */
		};

		/* node '/soc/venc@58005000' defined in zephyr/dts/arm/st/n6/stm32n6.dtsi:1315 */
		venc: venc@58005000 {
			compatible = "st,stm32-venc"; /* in zephyr/dts/arm/st/n6/stm32n6.dtsi:1316 */
			reg = < 0x58005000 0x1000 >;  /* in zephyr/dts/arm/st/n6/stm32n6.dtsi:1317 */
			interrupts = < 0x3e 0x0 >;    /* in zephyr/dts/arm/st/n6/stm32n6.dtsi:1318 */
			clocks = < &rcc 0x27c 0x20 >; /* in zephyr/dts/arm/st/n6/stm32n6.dtsi:1319 */
			resets = < &rctl 0x4785 >;    /* in zephyr/dts/arm/st/n6/stm32n6.dtsi:1320 */
			status = "disabled";          /* in zephyr/dts/arm/st/n6/stm32n6.dtsi:1321 */
		};

		/* node '/soc/codec@58023000' defined in zephyr/dts/arm/st/n6/stm32n6.dtsi:1324 */
		jpeg: codec@58023000 {
			compatible = "st,stm32-jpeg"; /* in zephyr/dts/arm/st/n6/stm32n6.dtsi:1325 */
			reg = < 0x58023000 0x1000 >;  /* in zephyr/dts/arm/st/n6/stm32n6.dtsi:1326 */
			interrupts = < 0x3d 0x0 >;    /* in zephyr/dts/arm/st/n6/stm32n6.dtsi:1327 */
			clocks = < &rcc 0x260 0x8 >;  /* in zephyr/dts/arm/st/n6/stm32n6.dtsi:1328 */
			resets = < &rctl 0x4403 >;    /* in zephyr/dts/arm/st/n6/stm32n6.dtsi:1329 */
			status = "disabled";          /* in zephyr/dts/arm/st/n6/stm32n6.dtsi:1330 */
		};
	};

	/* node '/cpus' defined in zephyr/dts/arm/st/n6/stm32n6.dtsi:24 */
	cpus {
		#address-cells = < 0x1 >; /* in zephyr/dts/arm/st/n6/stm32n6.dtsi:25 */
		#size-cells = < 0x0 >;    /* in zephyr/dts/arm/st/n6/stm32n6.dtsi:26 */

		/* node '/cpus/cpu@0' defined in zephyr/dts/arm/st/n6/stm32n6.dtsi:28 */
		cpu0: cpu@0 {
			device_type = "cpu";           /* in zephyr/dts/arm/st/n6/stm32n6.dtsi:29 */
			compatible = "arm,cortex-m55"; /* in zephyr/dts/arm/st/n6/stm32n6.dtsi:30 */
			reg = < 0x0 >;                 /* in zephyr/dts/arm/st/n6/stm32n6.dtsi:31 */
			#address-cells = < 0x1 >;      /* in zephyr/dts/arm/st/n6/stm32n6.dtsi:32 */
			#size-cells = < 0x1 >;         /* in zephyr/dts/arm/st/n6/stm32n6.dtsi:33 */

			/* node '/cpus/cpu@0/mpu@e000ed90' defined in zephyr/dts/arm/st/n6/stm32n6.dtsi:35 */
			mpu: mpu@e000ed90 {
				compatible = "arm,armv8.1m-mpu"; /* in zephyr/dts/arm/st/n6/stm32n6.dtsi:36 */
				reg = < 0xe000ed90 0x40 >;       /* in zephyr/dts/arm/st/n6/stm32n6.dtsi:37 */
			};
		};
	};

	/* node '/memory@34000000' defined in zephyr/dts/arm/st/n6/stm32n6.dtsi:42 */
	axisram1: memory@34000000 {
		compatible = "zephyr,memory-region",
		             "mmio-sram";            /* in zephyr/dts/arm/st/n6/stm32n6.dtsi:43 */
		zephyr,memory-region = "AXISRAM1";   /* in zephyr/dts/arm/st/n6/stm32n6.dtsi:44 */
		reg = < 0x34000000 0x200000 >;       /* in zephyr/dts/arm/st/n6/stm32n657X0.dtsi:12 */
	};

	/* node '/memory@34180400' defined in zephyr/dts/arm/st/n6/stm32n6.dtsi:47 */
	axisram2: memory@34180400 {
		compatible = "zephyr,memory-region",
		             "mmio-sram";            /* in zephyr/dts/arm/st/n6/stm32n6.dtsi:48 */
		zephyr,memory-region = "AXISRAM2";   /* in zephyr/dts/arm/st/n6/stm32n6.dtsi:49 */
		reg = < 0x34180400 0x7fc00 >;        /* in zephyr/dts/arm/st/n6/stm32n657X0.dtsi:17 */
	};

	/* node '/clocks' defined in zephyr/dts/arm/st/n6/stm32n6.dtsi:52 */
	clocks {

		/* node '/clocks/clk-hse' defined in zephyr/dts/arm/st/n6/stm32n6.dtsi:53 */
		clk_hse: clk-hse {
			#clock-cells = < 0x0 >;              /* in zephyr/dts/arm/st/n6/stm32n6.dtsi:54 */
			compatible = "st,stm32n6-hse-clock"; /* in zephyr/dts/arm/st/n6/stm32n6.dtsi:55 */
			hse-div2;                            /* in zephyr/boards/st/nucleo_n657x0_q/nucleo_n657x0_q_common.dtsi:88 */
			clock-frequency = < 0x2dc6c00 >;     /* in zephyr/boards/st/nucleo_n657x0_q/nucleo_n657x0_q_common.dtsi:89 */
			status = "okay";                     /* in zephyr/boards/st/nucleo_n657x0_q/nucleo_n657x0_q_common.dtsi:90 */
			phandle = < 0x2e >;                  /* in zephyr/boards/st/nucleo_n657x0_q/nucleo_n657x0_q_common.dtsi:99 */
		};

		/* node '/clocks/clk-hsi' defined in zephyr/dts/arm/st/n6/stm32n6.dtsi:59 */
		clk_hsi: clk-hsi {
			#clock-cells = < 0x0 >;              /* in zephyr/dts/arm/st/n6/stm32n6.dtsi:60 */
			compatible = "st,stm32h7-hsi-clock"; /* in zephyr/dts/arm/st/n6/stm32n6.dtsi:61 */
			clock-frequency = < 0x3d09000 >;     /* in zephyr/dts/arm/st/n6/stm32n6.dtsi:62 */
			hsi-div = < 0x1 >;                   /* in zephyr/boards/st/nucleo_n657x0_q/nucleo_n657x0_q_common.dtsi:94 */
			status = "okay";                     /* in zephyr/boards/st/nucleo_n657x0_q/nucleo_n657x0_q_common.dtsi:95 */
		};

		/* node '/clocks/clk-lse' defined in zephyr/dts/arm/st/n6/stm32n6.dtsi:66 */
		clk_lse: clk-lse {
			#clock-cells = < 0x0 >;            /* in zephyr/dts/arm/st/n6/stm32n6.dtsi:67 */
			compatible = "st,stm32-lse-clock"; /* in zephyr/dts/arm/st/n6/stm32n6.dtsi:68 */
			clock-frequency = < 0x8000 >;      /* in zephyr/dts/arm/st/n6/stm32n6.dtsi:69 */
			driving-capability = < 0x2 >;      /* in zephyr/dts/arm/st/n6/stm32n6.dtsi:70 */
			status = "disabled";               /* in zephyr/dts/arm/st/n6/stm32n6.dtsi:71 */
		};

		/* node '/clocks/clk-lsi' defined in zephyr/dts/arm/st/n6/stm32n6.dtsi:74 */
		clk_lsi: clk-lsi {
			#clock-cells = < 0x0 >;       /* in zephyr/dts/arm/st/n6/stm32n6.dtsi:75 */
			compatible = "fixed-clock";   /* in zephyr/dts/arm/st/n6/stm32n6.dtsi:76 */
			clock-frequency = < 0x7d00 >; /* in zephyr/dts/arm/st/n6/stm32n6.dtsi:77 */
			status = "disabled";          /* in zephyr/dts/arm/st/n6/stm32n6.dtsi:78 */
		};

		/* node '/clocks/pll' defined in zephyr/dts/arm/st/n6/stm32n6.dtsi:81 */
		pll1: pll: pll {
			#clock-cells = < 0x0 >;              /* in zephyr/dts/arm/st/n6/stm32n6.dtsi:82 */
			compatible = "st,stm32n6-pll-clock"; /* in zephyr/dts/arm/st/n6/stm32n6.dtsi:83 */
			clocks = < &clk_hse >;               /* in zephyr/boards/st/nucleo_n657x0_q/nucleo_n657x0_q_common.dtsi:99 */
			div-m = < 0x3 >;                     /* in zephyr/boards/st/nucleo_n657x0_q/nucleo_n657x0_q_common.dtsi:100 */
			mul-n = < 0x96 >;                    /* in zephyr/boards/st/nucleo_n657x0_q/nucleo_n657x0_q_common.dtsi:101 */
			div-p1 = < 0x1 >;                    /* in zephyr/boards/st/nucleo_n657x0_q/nucleo_n657x0_q_common.dtsi:102 */
			div-p2 = < 0x1 >;                    /* in zephyr/boards/st/nucleo_n657x0_q/nucleo_n657x0_q_common.dtsi:103 */
			status = "okay";                     /* in zephyr/boards/st/nucleo_n657x0_q/nucleo_n657x0_q_common.dtsi:104 */
		};

		/* node '/clocks/pll2' defined in zephyr/dts/arm/st/n6/stm32n6.dtsi:87 */
		pll2: pll2 {
			#clock-cells = < 0x0 >;              /* in zephyr/dts/arm/st/n6/stm32n6.dtsi:88 */
			compatible = "st,stm32n6-pll-clock"; /* in zephyr/dts/arm/st/n6/stm32n6.dtsi:89 */
			status = "disabled";                 /* in zephyr/dts/arm/st/n6/stm32n6.dtsi:90 */
		};

		/* node '/clocks/pll3' defined in zephyr/dts/arm/st/n6/stm32n6.dtsi:93 */
		pll3: pll3 {
			#clock-cells = < 0x0 >;              /* in zephyr/dts/arm/st/n6/stm32n6.dtsi:94 */
			compatible = "st,stm32n6-pll-clock"; /* in zephyr/dts/arm/st/n6/stm32n6.dtsi:95 */
			clocks = < &clk_hse >;               /* in zephyr/boards/st/nucleo_n657x0_q/nucleo_n657x0_q_common.dtsi:108 */
			div-m = < 0x3 >;                     /* in zephyr/boards/st/nucleo_n657x0_q/nucleo_n657x0_q_common.dtsi:109 */
			mul-n = < 0x7d >;                    /* in zephyr/boards/st/nucleo_n657x0_q/nucleo_n657x0_q_common.dtsi:110 */
			div-p1 = < 0x1 >;                    /* in zephyr/boards/st/nucleo_n657x0_q/nucleo_n657x0_q_common.dtsi:111 */
			div-p2 = < 0x1 >;                    /* in zephyr/boards/st/nucleo_n657x0_q/nucleo_n657x0_q_common.dtsi:112 */
			status = "okay";                     /* in zephyr/boards/st/nucleo_n657x0_q/nucleo_n657x0_q_common.dtsi:113 */
		};

		/* node '/clocks/pll4' defined in zephyr/dts/arm/st/n6/stm32n6.dtsi:99 */
		pll4: pll4 {
			#clock-cells = < 0x0 >;              /* in zephyr/dts/arm/st/n6/stm32n6.dtsi:100 */
			compatible = "st,stm32n6-pll-clock"; /* in zephyr/dts/arm/st/n6/stm32n6.dtsi:101 */
			status = "disabled";                 /* in zephyr/dts/arm/st/n6/stm32n6.dtsi:102 */
		};

		/* node '/clocks/cpusw' defined in zephyr/dts/arm/st/n6/stm32n6.dtsi:105 */
		cpusw: cpusw {
			#clock-cells = < 0x0 >;                  /* in zephyr/dts/arm/st/n6/stm32n6.dtsi:106 */
			compatible = "st,stm32n6-cpu-clock-mux",
			             "st,stm32-clock-mux";       /* in zephyr/dts/arm/st/n6/stm32n6.dtsi:107 */
			clocks = < &rcc 0xc 0x3300020 >;         /* in zephyr/boards/st/nucleo_n657x0_q/nucleo_n657x0_q_common.dtsi:159 */
			clock-frequency = < 0x2faf0800 >;        /* in zephyr/boards/st/nucleo_n657x0_q/nucleo_n657x0_q_common.dtsi:160 */
			status = "okay";                         /* in zephyr/boards/st/nucleo_n657x0_q/nucleo_n657x0_q_common.dtsi:161 */
		};

		/* node '/clocks/perck' defined in zephyr/dts/arm/st/n6/stm32n6.dtsi:111 */
		perck: perck {
			#clock-cells = < 0x0 >;            /* in zephyr/dts/arm/st/n6/stm32n6.dtsi:112 */
			compatible = "st,stm32-clock-mux"; /* in zephyr/dts/arm/st/n6/stm32n6.dtsi:113 */
			clocks = < &rcc 0x5 0x40015c >;    /* in zephyr/boards/st/nucleo_n657x0_q/nucleo_n657x0_q_common.dtsi:154 */
			status = "okay";                   /* in zephyr/boards/st/nucleo_n657x0_q/nucleo_n657x0_q_common.dtsi:155 */
		};

		/* node '/clocks/ic1' defined in zephyr/dts/arm/st/n6/stm32n6.dtsi:117 */
		ic1: ic1 {
			#clock-cells = < 0x0 >;                 /* in zephyr/dts/arm/st/n6/stm32n6.dtsi:118 */
			compatible = "st,stm32n6-ic-clock-mux"; /* in zephyr/dts/arm/st/n6/stm32n6.dtsi:119 */
			pll-src = < 0x1 >;                      /* in zephyr/boards/st/nucleo_n657x0_q/nucleo_n657x0_q_common.dtsi:117 */
			ic-div = < 0x3 >;                       /* in zephyr/boards/st/nucleo_n657x0_q/nucleo_n657x0_q_common.dtsi:118 */
			status = "okay";                        /* in zephyr/boards/st/nucleo_n657x0_q/nucleo_n657x0_q_common.dtsi:119 */
		};

		/* node '/clocks/ic2' defined in zephyr/dts/arm/st/n6/stm32n6.dtsi:123 */
		ic2: ic2 {
			#clock-cells = < 0x0 >;                 /* in zephyr/dts/arm/st/n6/stm32n6.dtsi:124 */
			compatible = "st,stm32n6-ic-clock-mux"; /* in zephyr/dts/arm/st/n6/stm32n6.dtsi:125 */
			pll-src = < 0x1 >;                      /* in zephyr/boards/st/nucleo_n657x0_q/nucleo_n657x0_q_common.dtsi:123 */
			ic-div = < 0x6 >;                       /* in zephyr/boards/st/nucleo_n657x0_q/nucleo_n657x0_q_common.dtsi:124 */
			status = "okay";                        /* in zephyr/boards/st/nucleo_n657x0_q/nucleo_n657x0_q_common.dtsi:125 */
			phandle = < 0x2 >;                      /* in zephyr/boards/st/nucleo_n657x0_q/nucleo_n657x0_q_common.dtsi:166 */
		};

		/* node '/clocks/ic3' defined in zephyr/dts/arm/st/n6/stm32n6.dtsi:129 */
		ic3: ic3 {
			#clock-cells = < 0x0 >;                 /* in zephyr/dts/arm/st/n6/stm32n6.dtsi:130 */
			compatible = "st,stm32n6-ic-clock-mux"; /* in zephyr/dts/arm/st/n6/stm32n6.dtsi:131 */
			status = "disabled";                    /* in zephyr/dts/arm/st/n6/stm32n6.dtsi:132 */
		};

		/* node '/clocks/ic4' defined in zephyr/dts/arm/st/n6/stm32n6.dtsi:135 */
		ic4: ic4 {
			#clock-cells = < 0x0 >;                 /* in zephyr/dts/arm/st/n6/stm32n6.dtsi:136 */
			compatible = "st,stm32n6-ic-clock-mux"; /* in zephyr/dts/arm/st/n6/stm32n6.dtsi:137 */
			status = "disabled";                    /* in zephyr/dts/arm/st/n6/stm32n6.dtsi:138 */
		};

		/* node '/clocks/ic5' defined in zephyr/dts/arm/st/n6/stm32n6.dtsi:141 */
		ic5: ic5 {
			#clock-cells = < 0x0 >;                 /* in zephyr/dts/arm/st/n6/stm32n6.dtsi:142 */
			compatible = "st,stm32n6-ic-clock-mux"; /* in zephyr/dts/arm/st/n6/stm32n6.dtsi:143 */
			status = "disabled";                    /* in zephyr/dts/arm/st/n6/stm32n6.dtsi:144 */
		};

		/* node '/clocks/ic6' defined in zephyr/dts/arm/st/n6/stm32n6.dtsi:147 */
		ic6: ic6 {
			#clock-cells = < 0x0 >;                 /* in zephyr/dts/arm/st/n6/stm32n6.dtsi:148 */
			compatible = "st,stm32n6-ic-clock-mux"; /* in zephyr/dts/arm/st/n6/stm32n6.dtsi:149 */
			pll-src = < 0x3 >;                      /* in zephyr/boards/st/nucleo_n657x0_q/nucleo_n657x0_q_common.dtsi:129 */
			ic-div = < 0x2 >;                       /* in zephyr/boards/st/nucleo_n657x0_q/nucleo_n657x0_q_common.dtsi:130 */
			status = "okay";                        /* in zephyr/boards/st/nucleo_n657x0_q/nucleo_n657x0_q_common.dtsi:131 */
		};

		/* node '/clocks/ic7' defined in zephyr/dts/arm/st/n6/stm32n6.dtsi:153 */
		ic7: ic7 {
			#clock-cells = < 0x0 >;                 /* in zephyr/dts/arm/st/n6/stm32n6.dtsi:154 */
			compatible = "st,stm32n6-ic-clock-mux"; /* in zephyr/dts/arm/st/n6/stm32n6.dtsi:155 */
			status = "disabled";                    /* in zephyr/dts/arm/st/n6/stm32n6.dtsi:156 */
		};

		/* node '/clocks/ic8' defined in zephyr/dts/arm/st/n6/stm32n6.dtsi:159 */
		ic8: ic8 {
			#clock-cells = < 0x0 >;                 /* in zephyr/dts/arm/st/n6/stm32n6.dtsi:160 */
			compatible = "st,stm32n6-ic-clock-mux"; /* in zephyr/dts/arm/st/n6/stm32n6.dtsi:161 */
			status = "disabled";                    /* in zephyr/dts/arm/st/n6/stm32n6.dtsi:162 */
		};

		/* node '/clocks/ic9' defined in zephyr/dts/arm/st/n6/stm32n6.dtsi:165 */
		ic9: ic9 {
			#clock-cells = < 0x0 >;                 /* in zephyr/dts/arm/st/n6/stm32n6.dtsi:166 */
			compatible = "st,stm32n6-ic-clock-mux"; /* in zephyr/dts/arm/st/n6/stm32n6.dtsi:167 */
			status = "disabled";                    /* in zephyr/dts/arm/st/n6/stm32n6.dtsi:168 */
		};

		/* node '/clocks/ic10' defined in zephyr/dts/arm/st/n6/stm32n6.dtsi:171 */
		ic10: ic10 {
			#clock-cells = < 0x0 >;                 /* in zephyr/dts/arm/st/n6/stm32n6.dtsi:172 */
			compatible = "st,stm32n6-ic-clock-mux"; /* in zephyr/dts/arm/st/n6/stm32n6.dtsi:173 */
			status = "disabled";                    /* in zephyr/dts/arm/st/n6/stm32n6.dtsi:174 */
		};

		/* node '/clocks/ic11' defined in zephyr/dts/arm/st/n6/stm32n6.dtsi:177 */
		ic11: ic11 {
			#clock-cells = < 0x0 >;                 /* in zephyr/dts/arm/st/n6/stm32n6.dtsi:178 */
			compatible = "st,stm32n6-ic-clock-mux"; /* in zephyr/dts/arm/st/n6/stm32n6.dtsi:179 */
			pll-src = < 0x1 >;                      /* in zephyr/boards/st/nucleo_n657x0_q/nucleo_n657x0_q_common.dtsi:135 */
			ic-div = < 0x3 >;                       /* in zephyr/boards/st/nucleo_n657x0_q/nucleo_n657x0_q_common.dtsi:136 */
			status = "okay";                        /* in zephyr/boards/st/nucleo_n657x0_q/nucleo_n657x0_q_common.dtsi:137 */
		};

		/* node '/clocks/ic12' defined in zephyr/dts/arm/st/n6/stm32n6.dtsi:183 */
		ic12: ic12 {
			#clock-cells = < 0x0 >;                 /* in zephyr/dts/arm/st/n6/stm32n6.dtsi:184 */
			compatible = "st,stm32n6-ic-clock-mux"; /* in zephyr/dts/arm/st/n6/stm32n6.dtsi:185 */
			status = "disabled";                    /* in zephyr/dts/arm/st/n6/stm32n6.dtsi:186 */
		};

		/* node '/clocks/ic13' defined in zephyr/dts/arm/st/n6/stm32n6.dtsi:189 */
		ic13: ic13 {
			#clock-cells = < 0x0 >;                 /* in zephyr/dts/arm/st/n6/stm32n6.dtsi:190 */
			compatible = "st,stm32n6-ic-clock-mux"; /* in zephyr/dts/arm/st/n6/stm32n6.dtsi:191 */
			status = "disabled";                    /* in zephyr/dts/arm/st/n6/stm32n6.dtsi:192 */
		};

		/* node '/clocks/ic14' defined in zephyr/dts/arm/st/n6/stm32n6.dtsi:195 */
		ic14: ic14 {
			#clock-cells = < 0x0 >;                 /* in zephyr/dts/arm/st/n6/stm32n6.dtsi:196 */
			compatible = "st,stm32n6-ic-clock-mux"; /* in zephyr/dts/arm/st/n6/stm32n6.dtsi:197 */
			status = "disabled";                    /* in zephyr/dts/arm/st/n6/stm32n6.dtsi:198 */
		};

		/* node '/clocks/ic15' defined in zephyr/dts/arm/st/n6/stm32n6.dtsi:201 */
		ic15: ic15 {
			#clock-cells = < 0x0 >;                 /* in zephyr/dts/arm/st/n6/stm32n6.dtsi:202 */
			compatible = "st,stm32n6-ic-clock-mux"; /* in zephyr/dts/arm/st/n6/stm32n6.dtsi:203 */
			status = "disabled";                    /* in zephyr/dts/arm/st/n6/stm32n6.dtsi:204 */
		};

		/* node '/clocks/ic16' defined in zephyr/dts/arm/st/n6/stm32n6.dtsi:207 */
		ic16: ic16 {
			#clock-cells = < 0x0 >;                 /* in zephyr/dts/arm/st/n6/stm32n6.dtsi:208 */
			compatible = "st,stm32n6-ic-clock-mux"; /* in zephyr/dts/arm/st/n6/stm32n6.dtsi:209 */
			status = "disabled";                    /* in zephyr/dts/arm/st/n6/stm32n6.dtsi:210 */
		};

		/* node '/clocks/ic17' defined in zephyr/dts/arm/st/n6/stm32n6.dtsi:213 */
		ic17: ic17 {
			#clock-cells = < 0x0 >;                 /* in zephyr/dts/arm/st/n6/stm32n6.dtsi:214 */
			compatible = "st,stm32n6-ic-clock-mux"; /* in zephyr/dts/arm/st/n6/stm32n6.dtsi:215 */
			pll-src = < 0x1 >;                      /* in zephyr/boards/st/nucleo_n657x0_q/nucleo_n657x0_q_common.dtsi:141 */
			ic-div = < 0x4 >;                       /* in zephyr/boards/st/nucleo_n657x0_q/nucleo_n657x0_q_common.dtsi:142 */
			status = "okay";                        /* in zephyr/boards/st/nucleo_n657x0_q/nucleo_n657x0_q_common.dtsi:143 */
		};

		/* node '/clocks/ic18' defined in zephyr/dts/arm/st/n6/stm32n6.dtsi:219 */
		ic18: ic18 {
			#clock-cells = < 0x0 >;                 /* in zephyr/dts/arm/st/n6/stm32n6.dtsi:220 */
			compatible = "st,stm32n6-ic-clock-mux"; /* in zephyr/dts/arm/st/n6/stm32n6.dtsi:221 */
			pll-src = < 0x1 >;                      /* in zephyr/boards/st/nucleo_n657x0_q/nucleo_n657x0_q_common.dtsi:148 */
			ic-div = < 0x3c >;                      /* in zephyr/boards/st/nucleo_n657x0_q/nucleo_n657x0_q_common.dtsi:149 */
			status = "okay";                        /* in zephyr/boards/st/nucleo_n657x0_q/nucleo_n657x0_q_common.dtsi:150 */
		};

		/* node '/clocks/ic19' defined in zephyr/dts/arm/st/n6/stm32n6.dtsi:225 */
		ic19: ic19 {
			#clock-cells = < 0x0 >;                 /* in zephyr/dts/arm/st/n6/stm32n6.dtsi:226 */
			compatible = "st,stm32n6-ic-clock-mux"; /* in zephyr/dts/arm/st/n6/stm32n6.dtsi:227 */
			status = "disabled";                    /* in zephyr/dts/arm/st/n6/stm32n6.dtsi:228 */
		};

		/* node '/clocks/ic20' defined in zephyr/dts/arm/st/n6/stm32n6.dtsi:231 */
		ic20: ic20 {
			#clock-cells = < 0x0 >;                 /* in zephyr/dts/arm/st/n6/stm32n6.dtsi:232 */
			compatible = "st,stm32n6-ic-clock-mux"; /* in zephyr/dts/arm/st/n6/stm32n6.dtsi:233 */
			status = "disabled";                    /* in zephyr/dts/arm/st/n6/stm32n6.dtsi:234 */
		};
	};

	/* node '/connector' defined in zephyr/boards/st/nucleo_n657x0_q/arduino_r3_connector.dtsi:10 */
	arduino_header: connector {
		compatible = "arduino-header-r3";          /* in zephyr/boards/st/nucleo_n657x0_q/arduino_r3_connector.dtsi:11 */
		#gpio-cells = < 0x2 >;                     /* in zephyr/boards/st/nucleo_n657x0_q/arduino_r3_connector.dtsi:12 */
		gpio-map-mask = < 0xffffffff 0xffffffc0 >; /* in zephyr/boards/st/nucleo_n657x0_q/arduino_r3_connector.dtsi:13 */
		gpio-map-pass-thru = < 0x0 0x3f >;         /* in zephyr/boards/st/nucleo_n657x0_q/arduino_r3_connector.dtsi:14 */
		gpio-map = < 0x0 0x0 &gpioa 0x8 0x0 >,
		           < 0x1 0x0 &gpioa 0x9 0x0 >,
		           < 0x2 0x0 &gpioa 0xa 0x0 >,
		           < 0x3 0x0 &gpioa 0xc 0x0 >,
		           < 0x4 0x0 &gpiof 0x3 0x0 >,
		           < 0x5 0x0 &gpiog 0xf 0x0 >,
		           < 0x6 0x0 &gpiod 0x9 0x0 >,
		           < 0x7 0x0 &gpiod 0x8 0x0 >,
		           < 0x8 0x0 &gpiod 0x0 0x0 >,
		           < 0x9 0x0 &gpioe 0x9 0x0 >,
		           < 0xa 0x0 &gpioe 0x0 0x0 >,
		           < 0xb 0x0 &gpioe 0xa 0x0 >,
		           < 0xc 0x0 &gpiod 0x5 0x0 >,
		           < 0xd 0x0 &gpioe 0xb 0x0 >,
		           < 0xe 0x0 &gpiod 0xc 0x0 >,
		           < 0xf 0x0 &gpiod 0x7 0x0 >,
		           < 0x10 0x0 &gpioa 0x3 0x0 >,
		           < 0x11 0x0 &gpiog 0x2 0x0 >,
		           < 0x12 0x0 &gpiog 0x1 0x0 >,
		           < 0x13 0x0 &gpioe 0xf 0x0 >,
		           < 0x14 0x0 &gpioc 0x1 0x0 >,
		           < 0x15 0x0 &gpioh 0x9 0x0 >;    /* in zephyr/boards/st/nucleo_n657x0_q/arduino_r3_connector.dtsi:15 */
	};

	/* node '/leds' defined in zephyr/boards/st/nucleo_n657x0_q/nucleo_n657x0_q_common.dtsi:23 */
	leds: leds {
		compatible = "gpio-leds"; /* in zephyr/boards/st/nucleo_n657x0_q/nucleo_n657x0_q_common.dtsi:24 */

		/* node '/leds/led_1' defined in zephyr/boards/st/nucleo_n657x0_q/nucleo_n657x0_q_common.dtsi:26 */
		green_led: led_1 {
			gpios = < &gpiog 0x0 0x1 >; /* in zephyr/boards/st/nucleo_n657x0_q/nucleo_n657x0_q_common.dtsi:27 */
			label = "User LD6";         /* in zephyr/boards/st/nucleo_n657x0_q/nucleo_n657x0_q_common.dtsi:28 */
		};

		/* node '/leds/led_2' defined in zephyr/boards/st/nucleo_n657x0_q/nucleo_n657x0_q_common.dtsi:31 */
		blue_led: led_2 {
			gpios = < &gpiog 0x8 0x1 >; /* in zephyr/boards/st/nucleo_n657x0_q/nucleo_n657x0_q_common.dtsi:32 */
			label = "User LD7";         /* in zephyr/boards/st/nucleo_n657x0_q/nucleo_n657x0_q_common.dtsi:33 */
		};

		/* node '/leds/led_3' defined in zephyr/boards/st/nucleo_n657x0_q/nucleo_n657x0_q_common.dtsi:36 */
		red_led: led_3 {
			gpios = < &gpiog 0xa 0x1 >; /* in zephyr/boards/st/nucleo_n657x0_q/nucleo_n657x0_q_common.dtsi:37 */
			label = "User LD5";         /* in zephyr/boards/st/nucleo_n657x0_q/nucleo_n657x0_q_common.dtsi:38 */
		};
	};

	/* node '/gpio_keys' defined in zephyr/boards/st/nucleo_n657x0_q/nucleo_n657x0_q_common.dtsi:42 */
	gpio_keys {
		compatible = "gpio-keys"; /* in zephyr/boards/st/nucleo_n657x0_q/nucleo_n657x0_q_common.dtsi:43 */

		/* node '/gpio_keys/button_0' defined in zephyr/boards/st/nucleo_n657x0_q/nucleo_n657x0_q_common.dtsi:45 */
		user_button: button_0 {
			gpios = < &gpioc 0xd 0x20 >; /* in zephyr/boards/st/nucleo_n657x0_q/nucleo_n657x0_q_common.dtsi:46 */
			label = "User SB1";          /* in zephyr/boards/st/nucleo_n657x0_q/nucleo_n657x0_q_common.dtsi:47 */
			zephyr,code = < 0xb >;       /* in zephyr/boards/st/nucleo_n657x0_q/nucleo_n657x0_q_common.dtsi:48 */
		};
	};

	/* node '/connector_csi' defined in zephyr/boards/st/nucleo_n657x0_q/nucleo_n657x0_q_common.dtsi:59 */
	csi_connector: connector_csi {
		compatible = "raspberrypi,csi-connector";  /* in zephyr/boards/st/nucleo_n657x0_q/nucleo_n657x0_q_common.dtsi:60 */
		#gpio-cells = < 0x2 >;                     /* in zephyr/boards/st/nucleo_n657x0_q/nucleo_n657x0_q_common.dtsi:61 */
		gpio-map-mask = < 0xffffffff 0xffffffc0 >; /* in zephyr/boards/st/nucleo_n657x0_q/nucleo_n657x0_q_common.dtsi:62 */
		gpio-map-pass-thru = < 0x0 0x3f >;         /* in zephyr/boards/st/nucleo_n657x0_q/nucleo_n657x0_q_common.dtsi:63 */
		gpio-map = < 0x1 0x0 &gpioo 0x5 0x0 >,
		           < 0x2 0x0 &gpioa 0x0 0x0 >;     /* in zephyr/boards/st/nucleo_n657x0_q/nucleo_n657x0_q_common.dtsi:64 */
	};
};
